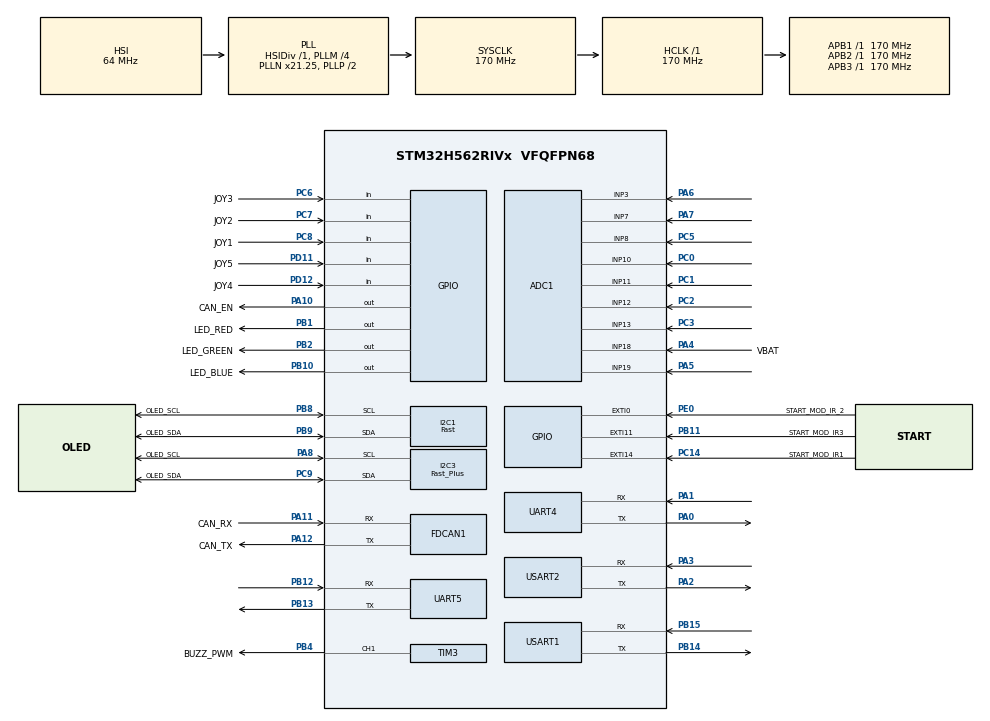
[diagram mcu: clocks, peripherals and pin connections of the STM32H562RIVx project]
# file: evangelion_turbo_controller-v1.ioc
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ADC1.Channel-0\#ChannelRegularConversion=ADC_CHANNEL_3
ADC1.Channel-1\#ChannelRegularConversion=ADC_CHANNEL_7
ADC1.Channel-2\#ChannelRegularConversion=ADC_CHANNEL_8
ADC1.Channel-3\#ChannelRegularConversion=ADC_CHANNEL_10
ADC1.Channel-4\#ChannelRegularConversion=ADC_CHANNEL_11
ADC1.Channel-5\#ChannelRegularConversion=ADC_CHANNEL_12
ADC1.Channel-6\#ChannelRegularConversion=ADC_CHANNEL_13
ADC1.Channel-7\#ChannelRegularConversion=ADC_CHANNEL_18
ADC1.Channel-8\#ChannelRegularConversion=ADC_CHANNEL_19
ADC1.ContinuousConvMode=ENABLE
ADC1.ConversionDataManagement=ADC_CONVERSIONDATA_DMA_CIRCULAR
ADC1.DMAContinuousRequests=ENABLE
ADC1.MonitoredBy-0\#ChannelRegularConversion=__NULL
ADC1.MonitoredBy-1\#ChannelRegularConversion=__NULL
ADC1.MonitoredBy-2\#ChannelRegularConversion=__NULL
ADC1.MonitoredBy-3\#ChannelRegularConversion=__NULL
ADC1.MonitoredBy-4\#ChannelRegularConversion=__NULL
ADC1.MonitoredBy-5\#ChannelRegularConversion=__NULL
ADC1.MonitoredBy-6\#ChannelRegularConversion=__NULL
ADC1.MonitoredBy-7\#ChannelRegularConversion=__NULL
ADC1.MonitoredBy-8\#ChannelRegularConversion=__NULL
ADC1.NbrOfConversion=9
ADC1.NbrOfConversionFlag=1
ADC1.OffsetNumber-0\#ChannelRegularConversion=ADC_OFFSET_NONE
ADC1.OffsetNumber-1\#ChannelRegularConversion=ADC_OFFSET_NONE
ADC1.OffsetNumber-2\#ChannelRegularConversion=ADC_OFFSET_NONE
ADC1.OffsetNumber-3\#ChannelRegularConversion=ADC_OFFSET_NONE
ADC1.OffsetNumber-4\#ChannelRegularConversion=ADC_OFFSET_NONE
ADC1.OffsetNumber-5\#ChannelRegularConversion=ADC_OFFSET_NONE
ADC1.OffsetNumber-6\#ChannelRegularConversion=ADC_OFFSET_NONE
ADC1.OffsetNumber-7\#ChannelRegularConversion=ADC_OFFSET_NONE
ADC1.OffsetNumber-8\#ChannelRegularConversion=ADC_OFFSET_NONE
ADC1.Overrun=ADC_OVR_DATA_OVERWRITTEN
ADC1.Rank-0\#ChannelRegularConversion=1
ADC1.Rank-1\#ChannelRegularConversion=2
ADC1.Rank-2\#ChannelRegularConversion=3
ADC1.Rank-3\#ChannelRegularConversion=4
ADC1.Rank-4\#ChannelRegularConversion=5
ADC1.Rank-5\#ChannelRegularConversion=6
ADC1.Rank-6\#ChannelRegularConversion=7
ADC1.Rank-7\#ChannelRegularConversion=8
ADC1.Rank-8\#ChannelRegularConversion=9
ADC1.SamplingTime-0\#ChannelRegularConversion=ADC_SAMPLETIME_6CYCLES_5
ADC1.SamplingTime-1\#ChannelRegularConversion=ADC_SAMPLETIME_6CYCLES_5
ADC1.SamplingTime-2\#ChannelRegularConversion=ADC_SAMPLETIME_6CYCLES_5
ADC1.SamplingTime-3\#ChannelRegularConversion=ADC_SAMPLETIME_6CYCLES_5
ADC1.SamplingTime-4\#ChannelRegularConversion=ADC_SAMPLETIME_6CYCLES_5
ADC1.SamplingTime-5\#ChannelRegularConversion=ADC_SAMPLETIME_6CYCLES_5
ADC1.SamplingTime-6\#ChannelRegularConversion=ADC_SAMPLETIME_6CYCLES_5
ADC1.SamplingTime-7\#ChannelRegularConversion=ADC_SAMPLETIME_6CYCLES_5
ADC1.SamplingTime-8\#ChannelRegularConversion=ADC_SAMPLETIME_24CYCLES_5
ADC1.master=1
BOOTPATH.BootPathName=LEGACY
BOOTPATH.UserSelectedBootPath=LEGACY
CORTEX_M33_NS.userName=CORTEX_M33
FDCAN1.AutoRetransmission=ENABLE
FDCAN1.CalculateBaudRateNominal=499999
FDCAN1.CalculateTimeBitNominal=2000
FDCAN1.CalculateTimeQuantumNominal=117.64705882352942
FDCAN1.DataPrescaler=20
FDCAN1.DataTimeSeg1=14
FDCAN1.DataTimeSeg2=2
FDCAN1.FrameFormat=FDCAN_FRAME_CLASSIC
FDCAN1.Mode=FDCAN_MODE_NORMAL
FDCAN1.NominalPrescaler=20
FDCAN1.NominalTimeSeg1=14
FDCAN1.NominalTimeSeg2=2
FDCAN1.StdFiltersNbr=1
GPDMA1.CIRCULARMODE_GPDMACH1=DISABLE
GPDMA1.CIRCULARMODE_GPDMACH2=DISABLE
GPDMA1.CIRCULARMODE_GPDMACH4=DISABLE
GPDMA1.CIRCULARMODE_GPDMACH5=DISABLE
GPDMA1.DATAHANDLING_GPDMACH2=NONE
GPDMA1.DESTBURSTLENGTH_GPDMACH2=1
GPDMA1.DESTDATAWIDTH_GPDMACH2=DMA_DEST_DATAWIDTH_BYTE
GPDMA1.DESTINC_GPDMACH1=DMA_DINC_INCREMENTED
GPDMA1.DESTINC_GPDMACH2=DMA_DINC_INCREMENTED
GPDMA1.DESTINC_GPDMACH4=DMA_DINC_INCREMENTED
GPDMA1.DESTINC_GPDMACH5=DMA_DINC_INCREMENTED
GPDMA1.IPHANDLE_GPDMACH1-SIMPLEREQUEST_GPDMACH1=__NULL
GPDMA1.IPHANDLE_GPDMACH2-SIMPLEREQUEST_GPDMACH2=__NULL
GPDMA1.IPHANDLE_GPDMACH4-SIMPLEREQUEST_GPDMACH4=__NULL
GPDMA1.IPHANDLE_GPDMACH5-SIMPLEREQUEST_GPDMACH5=__NULL
GPDMA1.LINKALLOCATEDPORT_CIRCULAR_GPDMACH4=DMA_LINK_ALLOCATED_PORT1
GPDMA1.LINKALLOCATEDPORT_CIRCULAR_GPDMACH5=DMA_LINK_ALLOCATED_PORT1
GPDMA1.PRIORITY_GPDMACH1=DMA_LOW_PRIORITY_HIGH_WEIGHT
GPDMA1.PRIORITY_GPDMACH2=DMA_LOW_PRIORITY_HIGH_WEIGHT
GPDMA1.PRIORITY_GPDMACH4=DMA_LOW_PRIORITY_HIGH_WEIGHT
GPDMA1.PRIORITY_GPDMACH5=DMA_LOW_PRIORITY_HIGH_WEIGHT
GPDMA1.REQUEST_GPDMACH1=GPDMA1_REQUEST_USART1_RX
GPDMA1.REQUEST_GPDMACH2=GPDMA1_REQUEST_USART2_RX
GPDMA1.REQUEST_GPDMACH4=GPDMA1_REQUEST_UART4_RX
GPDMA1.REQUEST_GPDMACH5=GPDMA1_REQUEST_UART5_RX
GPDMA1.SRCBURSTLENGTH_GPDMACH2=1
GPDMA1.SRCDATAWIDTH_GPDMACH1=DMA_SRC_DATAWIDTH_BYTE
GPDMA1.SRCDATAWIDTH_GPDMACH2=DMA_SRC_DATAWIDTH_BYTE
GPDMA1.SRCINC_GPDMACH2=DMA_SINC_FIXED
GPDMA2.CIRCULARMODE_GPDMACH0=ENABLE
GPDMA2.DESTDATAWIDTH_GPDMACH0=DMA_DEST_DATAWIDTH_HALFWORD
GPDMA2.DESTINC_GPDMACH0=DMA_DINC_INCREMENTED
GPDMA2.DESTINC_GPDMACH1=DMA_DINC_FIXED
GPDMA2.DIRECTION_GPDMACH1=DMA_MEMORY_TO_PERIPH
GPDMA2.IPHANDLE_GPDMACH0-SIMPLEREQUEST_GPDMACH0=__NULL
GPDMA2.IPHANDLE_GPDMACH1-SIMPLEREQUEST_GPDMACH1=__NULL
GPDMA2.LINKALLOCATEDPORT_CIRCULAR_GPDMACH0=DMA_LINK_ALLOCATED_PORT1
GPDMA2.PRIORITY_LL_CIRCULAR_GPDMACH0=DMA_LOW_PRIORITY_MID_WEIGHT
GPDMA2.REQUEST_GPDMACH0=GPDMA2_REQUEST_ADC1
GPDMA2.REQUEST_GPDMACH1=GPDMA2_REQUEST_I2C1_TX
GPDMA2.SRCDATAWIDTH_GPDMACH0=DMA_SRC_DATAWIDTH_HALFWORD
GPDMA2.SRCINC_GPDMACH1=DMA_SINC_INCREMENTED
I2C1.I2C_Speed_Mode=I2C_Fast
I2C1.Timing=0x10802D9B
I2C3.I2C_Speed_Mode=I2C_Fast_Plus
I2C3.Timing=0x00802172
Mcu.Family=STM32H5
Mcu.Name=STM32H562RIVx
Mcu.Package=VFQFPN68
NVIC.EXTI0_IRQn=true\:0\:0\:false\:false\:true\:true\:true\:true
NVIC.EXTI11_IRQn=true\:0\:0\:false\:false\:true\:true\:true\:true
NVIC.EXTI14_IRQn=true\:0\:0\:false\:false\:true\:true\:true\:true
NVIC.FDCAN1_IT0_IRQn=true\:0\:0\:false\:false\:true\:true\:true\:true
NVIC.FDCAN1_IT1_IRQn=true\:0\:0\:false\:false\:true\:true\:true\:true
NVIC.GPDMA1_Channel1_IRQn=true\:0\:0\:false\:false\:true\:false\:true\:true
NVIC.GPDMA1_Channel2_IRQn=true\:0\:0\:false\:false\:true\:false\:true\:true
NVIC.GPDMA1_Channel4_IRQn=true\:0\:0\:false\:false\:true\:false\:true\:true
NVIC.GPDMA1_Channel5_IRQn=true\:0\:0\:false\:false\:true\:false\:true\:true
NVIC.GPDMA2_Channel0_IRQn=true\:0\:0\:false\:false\:true\:false\:true\:true
NVIC.GPDMA2_Channel1_IRQn=true\:0\:0\:false\:false\:true\:false\:true\:true
NVIC.I2C1_EV_IRQn=true\:0\:0\:false\:false\:true\:true\:true\:true
NVIC.I2C3_ER_IRQn=true\:0\:0\:false\:false\:true\:true\:true\:true
NVIC.I2C3_EV_IRQn=true\:0\:0\:false\:false\:true\:true\:true\:true
NVIC.PriorityGroup=NVIC_PRIORITYGROUP_4
NVIC.TIM12_IRQn=true\:0\:0\:false\:false\:true\:true\:true\:true
NVIC.TIM13_IRQn=true\:0\:0\:false\:false\:true\:true\:true\:true
NVIC.TIM14_IRQn=true\:0\:0\:false\:false\:true\:true\:true\:true
NVIC.TIM15_IRQn=true\:0\:0\:false\:false\:true\:true\:true\:true
NVIC.TIM16_IRQn=true\:0\:0\:false\:false\:true\:true\:true\:true
NVIC.TIM17_IRQn=true\:0\:0\:false\:false\:true\:true\:true\:true
NVIC.TIM5_IRQn=true\:0\:0\:false\:false\:true\:true\:true\:true
NVIC.TIM6_IRQn=true\:0\:0\:false\:false\:true\:true\:true\:true
NVIC.TIM7_IRQn=true\:0\:0\:false\:false\:true\:true\:true\:true
NVIC.UART4_IRQn=true\:0\:0\:false\:false\:true\:true\:true\:true
NVIC.UART5_IRQn=true\:0\:0\:false\:false\:true\:true\:true\:true
NVIC.USART1_IRQn=true\:0\:0\:false\:false\:true\:true\:true\:true
NVIC.USART2_IRQn=true\:0\:0\:false\:false\:true\:true\:true\:true
PA0.Mode=Asynchronous
PA0.Signal=UART4_TX
PA1.Mode=Asynchronous
PA1.PinAttribute=Free
PA1.Signal=UART4_RX
PA10.GPIO_Label=CAN_EN
PA10.GPIO_PuPd=GPIO_PULLUP
PA10.PinAttribute=Free
PA10.Signal=GPIO_Output
PA11.GPIO_Label=CAN_RX
PA11.Mode=FDCAN_Activate
PA11.PinAttribute=Free
PA11.Signal=FDCAN1_RX
PA12.GPIO_Label=CAN_TX
PA12.Mode=FDCAN_Activate
PA12.PinAttribute=Free
PA12.Signal=FDCAN1_TX
PA13(JTMS/SWDIO).Mode=Serial_Wire
PA13(JTMS/SWDIO).Signal=DEBUG_JTMS-SWDIO
PA14(JTCK/SWCLK).Mode=Serial_Wire
PA14(JTCK/SWCLK).Signal=DEBUG_JTCK-SWCLK
PA2.Mode=Asynchronous
PA2.PinAttribute=Free
PA2.Signal=USART2_TX
PA3.Mode=Asynchronous
PA3.PinAttribute=Free
PA3.Signal=USART2_RX
PA4.GPIO_Label=VBAT
PA4.PinAttribute=Free
PA4.Signal=ADCx_INP18
PA5.PinAttribute=Free
PA5.Signal=ADCx_INP19
PA6.PinAttribute=Free
PA6.Signal=ADCx_INP3
PA7.PinAttribute=Free
PA7.Signal=ADCx_INP7
PA8.GPIO_Label=OLED_SCL
PA8.Mode=I2C
PA8.PinAttribute=Free
PA8.Signal=I2C3_SCL
PB1.GPIO_Label=LED_RED
PB1.PinAttribute=Free
PB1.Signal=GPIO_Output
PB10.GPIO_Label=LED_BLUE
PB10.PinAttribute=Free
PB10.Signal=GPIO_Output
PB11.GPIO_Label=START_MOD_IR3
PB11.GPIO_ModeDefaultEXTI=GPIO_MODE_IT_RISING_FALLING
PB11.GPIO_PuPd=GPIO_NOPULL
PB11.PinAttribute=Free
PB11.Signal=GPXTI11
PB12.Mode=Asynchronous
PB12.PinAttribute=Free
PB12.Signal=UART5_RX
PB13.Mode=Asynchronous
PB13.PinAttribute=Free
PB13.Signal=UART5_TX
PB14.Mode=Asynchronous
PB14.PinAttribute=Free
PB14.Signal=USART1_TX
PB15.Mode=Asynchronous
PB15.PinAttribute=Free
PB15.Signal=USART1_RX
PB2.GPIO_Label=LED_GREEN
PB2.PinAttribute=Free
PB2.Signal=GPIO_Output
PB4(NJTRST).GPIO_Label=BUZZ_PWM
PB4(NJTRST).PinAttribute=Free
PB4(NJTRST).Signal=S_TIM3_CH1
PB8.GPIO_Label=OLED_SCL
PB8.Mode=I2C
PB8.Signal=I2C1_SCL
PB9.GPIO_Label=OLED_SDA
PB9.Mode=I2C
PB9.Signal=I2C1_SDA
PC0.PinAttribute=Free
PC0.Signal=ADCx_INP10
PC1.Signal=ADCx_INP11
PC14-OSC32_IN(OSC32_IN).GPIO_Label=START_MOD_IR1
PC14-OSC32_IN(OSC32_IN).GPIO_ModeDefaultEXTI=GPIO_MODE_IT_RISING_FALLING
PC14-OSC32_IN(OSC32_IN).GPIO_PuPd=GPIO_NOPULL
PC14-OSC32_IN(OSC32_IN).Signal=GPXTI14
PC2.Signal=ADCx_INP12
PC3.Signal=ADCx_INP13
PC5.PinAttribute=Free
PC5.Signal=ADCx_INP8
PC6.GPIO_Label=JOY3
PC6.GPIO_PuPd=GPIO_PULLUP
PC6.PinAttribute=Free
PC6.Signal=GPIO_Input
PC7.GPIO_Label=JOY2
PC7.GPIO_PuPd=GPIO_PULLUP
PC7.PinAttribute=Free
PC7.Signal=GPIO_Input
PC8.GPIO_Label=JOY1
PC8.GPIO_PuPd=GPIO_PULLUP
PC8.PinAttribute=Free
PC8.Signal=GPIO_Input
PC9.GPIO_Label=OLED_SDA
PC9.Mode=I2C
PC9.PinAttribute=Free
PC9.Signal=I2C3_SDA
PD11.GPIO_Label=JOY5
PD11.GPIO_PuPd=GPIO_PULLUP
PD11.PinAttribute=Free
PD11.Signal=GPIO_Input
PD12.GPIO_Label=JOY4
PD12.GPIO_PuPd=GPIO_PULLUP
PD12.PinAttribute=Free
PD12.Signal=GPIO_Input
PE0.GPIO_Label=START_MOD_IR_2
PE0.GPIO_ModeDefaultEXTI=GPIO_MODE_IT_RISING_FALLING
PE0.GPIO_PuPd=GPIO_NOPULL
PE0.PinAttribute=Free
PE0.Signal=GPXTI0
ProjectManager.HeapSize=0x200
ProjectManager.StackSize=0x400
ProjectManager.TargetToolchain=STM32CubeIDE
RCC.ADCFreq_Value=170000000
RCC.AHBFreq_Value=170000000
RCC.APB1Freq_Value=170000000
RCC.APB1TimFreq_Value=170000000
RCC.APB2Freq_Value=170000000
RCC.APB2TimFreq_Value=170000000
RCC.APB3Freq_Value=170000000
RCC.CSI_VALUE=4000000
RCC.CortexFreq_Value=170000000
RCC.EPOD_VALUE=64000000
RCC.FDCANClockSelection=RCC_FDCANCLKSOURCE_PLL1Q
RCC.HCLKFreq_Value=170000000
RCC.HSE_Timout=200
RCC.HSE_VALUE=48000000
RCC.HSI48_VALUE=48000000
RCC.HSIDiv=RCC_HSI_DIV1
RCC.HSI_VALUE=64000000
RCC.LSE_VALUE=32768
RCC.LSIRC_VALUE=32000
RCC.PLL2FRACN=0
RCC.PLL2Source=RCC_PLL2_SOURCE_HSI
RCC.PLL3FRACN=0
RCC.PLL3Source=RCC_PLL3_SOURCE_HSI
RCC.PLL3_VCI_Range-AdvancedSettings=RCC_PLL3_VCIRANGE_0
RCC.PLLFRACN=2048
RCC.PLLM=4
RCC.PLLN=21
RCC.PLLSourceVirtual=RCC_PLL1_SOURCE_HSI
RCC.SYSCLKFreq_VALUE=170000000
RCC.SYSCLKSource=RCC_SYSCLKSOURCE_PLLCLK
RCC.USBFreq_Value=48000000
RCC.VCOOutputFreq_Value=340000000
SH.ADCx_INP10.0=ADC1_INP10,IN10-Single-Ended
SH.ADCx_INP11.0=ADC1_INP11,IN11-Single-Ended
SH.ADCx_INP12.0=ADC1_INP12,IN12-Single-Ended
SH.ADCx_INP13.0=ADC1_INP13,IN13-Single-Ended
SH.ADCx_INP18.0=ADC1_INP18,IN18-Single-Ended
SH.ADCx_INP19.0=ADC1_INP19,IN19-Single-Ended
SH.ADCx_INP3.0=ADC1_INP3,IN3-Single-Ended
SH.ADCx_INP7.0=ADC1_INP7,IN7-Single-Ended
SH.ADCx_INP8.0=ADC1_INP8,IN8-Single-Ended
SH.S_TIM3_CH1.0=TIM3_CH1,PWM Generation1 CH1
TIM12.PeriodNoDither=5000-1
TIM12.Prescaler=1700-1
TIM13.PeriodNoDither=1000-1
TIM13.Prescaler=170-1
TIM14.PeriodNoDither=1000-1
TIM14.Prescaler=6800-1
TIM15.PeriodNoDither=65535
TIM15.Prescaler=170-1
TIM16.PeriodNoDither=1000-1
TIM16.Prescaler=170-1
TIM17.PeriodNoDither=1000-1
TIM17.Prescaler=1700-1
TIM3.Channel-PWM\ Generation1\ CH1=TIM_CHANNEL_1
TIM4.Prescaler=17000-1
TIM5.PeriodNoDither=65535
TIM5.Prescaler=17000-1
TIM6.Prescaler=17000-1
TIM7.Prescaler=17000-1
UART4.DataInvertParam=UART_ADVFEATURE_DATAINV_DISABLE
UART4.SwapParam=UART_ADVFEATURE_SWAP_DISABLE
USART1.VirtualMode-Asynchronous=VM_ASYNC
USART2.VirtualMode-Asynchronous=VM_ASYNC
VP_BOOTPATH_VS_BOOTPATH.Mode=BP_Activate
VP_CORTEX_M33_NS_VS_Hclk.Mode=Hclk_Mode
VP_GPDMA1_VS_GPDMACH1.Mode=SIMPLEREQUEST_GPDMACH1
VP_GPDMA1_VS_GPDMACH2.Mode=SIMPLEREQUEST_GPDMACH2
VP_GPDMA1_VS_GPDMACH4.Mode=SIMPLEREQUEST_GPDMACH4
VP_GPDMA1_VS_GPDMACH5.Mode=SIMPLEREQUEST_GPDMACH5
VP_GPDMA2_VS_GPDMACH0.Mode=SIMPLEREQUEST_GPDMACH0
VP_GPDMA2_VS_GPDMACH1.Mode=SIMPLEREQUEST_GPDMACH1
VP_MEMORYMAP_VS_MEMORYMAP.Mode=CurAppReg
VP_PWR_VS_LPOM.Mode=PowerOptimisation
VP_PWR_VS_SECSignals.Mode=Security/Privilege
VP_TIM12_VS_ClockSourceINT.Mode=Internal
VP_TIM13_VS_ClockSourceINT.Mode=Enable_Timer
VP_TIM14_VS_ClockSourceINT.Mode=Enable_Timer
VP_TIM15_VS_ClockSourceINT.Mode=Internal
VP_TIM16_VS_ClockSourceINT.Mode=Enable_Timer
VP_TIM17_VS_ClockSourceINT.Mode=Enable_Timer
VP_TIM4_VS_OPM.Mode=OPM_bit
VP_TIM5_VS_OPM.Mode=OPM_bit
VP_TIM6_VS_ClockSourceINT.Mode=Enable_Timer
VP_TIM7_VS_ClockSourceINT.Mode=Enable_Timer
board=custom

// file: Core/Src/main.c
/* USER CODE BEGIN Header */
/**
  ******************************************************************************
  * @file           : main.c
  * @brief          : Main program body
  ******************************************************************************
  * @attention
  *
  * Copyright (c) 2026 STMicroelectronics.
  * All rights reserved.
  *
  * This software is licensed under terms that can be found in the LICENSE file
  * in the root directory of this software component.
  * If no LICENSE file comes with this software, it is provided AS-IS.
  *
  ******************************************************************************
  */
/* USER CODE END Header */
#include "main.h"

/* USER CODE BEGIN Includes */
#include "stdlib.h"
#include "MY_INCLUDES.h"

#include "fonts.h"
#include "ssd1306.h"
/* USER CODE END Includes */

/* USER CODE BEGIN PD */
#define DMA_HANDLE_UART1 &handle_GPDMA1_Channel1
#define DMA_HANDLE_UART2 &handle_GPDMA1_Channel2
#define DMA_HANDLE_UART4 &handle_GPDMA1_Channel4
#define DMA_HANDLE_UART5 &handle_GPDMA1_Channel5

#define CAN_ID_CTRL  60
#define CAN_ID_DRV0  67
#define CAN_ID_DRV1  69

//==================================================== WORKING SETUP
#define MAIN_FREQ 1000
#define SIDE_FREQ 100
#define OLED_FREQ 25
#define true 1
#define TRUE 1
#define false 0
#define FALSE 0
#define LEFT 0
#define RIGHT 1

//============etc
#define ABS(x) ((x) < 0 ? -(x) : (x))

//option IDs
#define OPTION_ID_BATTERY 1
#define OPTION_ID_START_MOD 2
#define OPTION_ID_LUNA_DIST 3
#define OPTION_ID_LUNA_AMP 4
#define OPTION_ID_LINES 6
#define OPTION_ID_ACCEL 7
#define OPTION_ID_GYRO 8
#define OPTION_ID_IMU_PEAK 9
#define OPTION_ID_SET_MOTS 10
#define OPTION_ID_DEBUG 11
#define OPTION_ID_ATTACK_MODE 12

//==================================================== BATTERY
#define BATTERY_VOLTAGE_COMPENSATION 	1
#define MIN_BATTERY_VOLTAGE_PER_CELL 	3.45
#define Reference_Voltage				3.311		// V
#define Voltage_Resistor_Top 			91.0		// kOhm
#define Voltage_Resistor_Bottom  		10.0		// kOhm
#define ADC_MAX_VALUE					4096

//==================================================== OLED
#define _ssd1306_SetCursor(x, y) ssd1306_SetCursor(y, x)
#define BIG 1
#define SMALL 0

#define _ARR_UP '('
#define _ARR_DOWN '@'
#define _CHECKBOX_EMPTY '^'
#define _CHECKBOX_CHECKED '$'
#define _CHECKBOX_EMPTY_BIG ')'
#define _CHECKBOX_CHECKED_BIG '\''
#define _CANCEL '}'
#define _APPLY '{'

//=============================================================================================================
//=============================================================================================================			START MOD CODE
//=============================================================================================================
#define RISING 		1
#define FALLING		2
#define TIMEOUT		3

#define RC5				1
#define SIRC			2
#define UNKNOWN			0
#define SAVED_STATUS 	5

#define RC5_Short   889      // 889 us
#define RC5_Long    1778     // 1778 us
#define SIRC_Short  600+50      // 600 us
#define SIRC_Long   1200+50     // 1200 us
#define Margin      300

// Module Status
#define STARTUP		1
#define	PPROGRAMMED	2
#define	READY		3
#define	RC5_START	4
#define SIRC_START	5
#define	STOP		6

// Led Commands
#define ON			2
#define OFF			3
#define BLINK_SLOW	4
#define BLINK_FAST	5
#define TICK		6

/* USER CODE END PD */

/* USER CODE BEGIN PM */
typedef struct {
	uint8_t DONT_USE_MOTORS;
	uint8_t ALWAYS_IN_BATTLE;
	uint8_t IGNORE_START_MODULE;
	uint8_t LINE_SENSORS_ALWAYS_IN;
	uint8_t IGNORE_ACCEL;
	uint8_t DONT_INITIALIZE_LIDARS;
} Settings_t;

typedef enum {
	IN,
	OUT
} LineState_t;

typedef enum {
	STRAIGHT,
	CURVE,
	FOLLOW_LINER,
	FOLLOW_ATTACKER,
	COUNT,
} RobotAttackMode_t;

typedef enum
{
	IDLE,
	BEFORE_ATTACK_WAIT,
	BEFORE_ATTACK_TASK,
	AFTER_TASK_RAM_QUCKIE,
	AFTER_TASK_RAM_CHILL,
	ATTACK,
} RobotState_t;

typedef enum {
	_NOTHING,
	_UP,
	_DOWN,
	_LEFT,
	_RIGHT,
	_CENTER,
	_BUTTON_REBOUNCE,
} JoystickMode_t;

typedef struct {
	LineState_t Line;
	uint16_t RawLineA;
	uint16_t RawLineB;
    uint16_t Distance;
    uint16_t LidarAmp;
    uint16_t LidarTemp;
} SensorData_t;

typedef struct {
	uint8_t Switch1;
	uint8_t Switch2;
	uint8_t Switch3;
	JoystickMode_t Joystick;
	uint8_t MenuOption;
} Interface_t;

typedef struct
{
	int16_t x;
	int16_t y;
	int16_t z;
	int16_t peak;
} Vector_t;

typedef struct {
	uint8_t inBattle;
	RobotAttackMode_t AttackMode;
	uint16_t Voltage;
	uint16_t CellVoltage;
	RobotState_t State;
	Interface_t Interface;
	uint8_t DriverTemp;
	uint16_t StartDelayTimer;
} RobotData_t;

typedef struct {
	uint8_t CurrentAddres;
	uint8_t Started;
	uint8_t StartedViaInterface;
	uint8_t StartedViaSwitch;
	uint16_t Delay;
	uint16_t VolatileDelayTimer;
} StartModData_t;

typedef struct
{
	int8_t L;
	int8_t R;
} Speed_t;

typedef struct
{
	uint8_t L;
	uint8_t R;
} Speed_directional_t;

typedef struct
{
	Speed_t Requested;
	Speed_t Set;
	Speed_directional_t CAN;
} MotorSpeed_t;

typedef struct {
    const char *name;
    uint8_t id;
} MenuOption_t;

/* USER CODE END PM */

ADC_HandleTypeDef hadc1;
DMA_NodeTypeDef Node_GPDMA2_Channel0;
DMA_QListTypeDef List_GPDMA2_Channel0;
DMA_HandleTypeDef handle_GPDMA2_Channel0;

FDCAN_HandleTypeDef hfdcan1;

I2C_HandleTypeDef hi2c1;
I2C_HandleTypeDef hi2c3;
DMA_HandleTypeDef handle_GPDMA2_Channel1;

TIM_HandleTypeDef htim3;
TIM_HandleTypeDef htim4;
TIM_HandleTypeDef htim5;
TIM_HandleTypeDef htim6;
TIM_HandleTypeDef htim7;
TIM_HandleTypeDef htim12;
TIM_HandleTypeDef htim13;
TIM_HandleTypeDef htim14;
TIM_HandleTypeDef htim15;
TIM_HandleTypeDef htim16;
TIM_HandleTypeDef htim17;

UART_HandleTypeDef huart4;
UART_HandleTypeDef huart5;
UART_HandleTypeDef huart1;
UART_HandleTypeDef huart2;
DMA_HandleTypeDef handle_GPDMA1_Channel4;
DMA_HandleTypeDef handle_GPDMA1_Channel5;
DMA_HandleTypeDef handle_GPDMA1_Channel1;
DMA_HandleTypeDef handle_GPDMA1_Channel2;

/* USER CODE BEGIN PV */
//CAN
FDCAN_RxHeaderTypeDef 		CAN_RX_Header; 		//CAN Bus Transmit Header
FDCAN_TxHeaderTypeDef 		CAN_TX_Header; 		//CAN Bus Receive Header
uint8_t                     CAN_TX[8];
uint8_t                     CAN_RX[8];
FDCAN_FilterTypeDef 		CAN_Filter;

volatile int32_t dupa=0;
volatile int32_t dupa2=0;
uint16_t actual_init_freq=FREQ_STARTING;
int16_t ERROR_FLAG=0;

//sensors
uint8_t  UART1_RX[9];
uint8_t  UART2_RX[9];
uint8_t  UART4_RX[9];
uint8_t  UART5_RX[9];
uint8_t  UART_TX[9];

SensorData_t FrontLeft={0};
SensorData_t FrontRight={0};
SensorData_t BackLeft={0};
SensorData_t BackRight={0};
RobotData_t Eva={0};
MotorSpeed_t Motors={0};
StartModData_t StartMod={0};
Settings_t Settings={0};

uint8_t lastSeen = LEFT;
uint8_t before_attack_rotation_direction = LEFT;

volatile uint16_t ADC_BUFFER[9];
float BATTERY_CONSTANT;

//performance!
static uint32_t last_total = 0;
static uint32_t last_idle = 0;
volatile uint32_t cpu_idle_cycles = 0;
volatile uint32_t cpu_load_permille = 0;
volatile uint8_t MCU_LOAD = 0;
volatile uint8_t MCU_LOAD_MAX = 0;

//============================		START MOD CODE
uint8_t Module_State = STARTUP;
static uint8_t Dohyo_ID=0;
uint8_t MAX_ACCELERATION=0;
/* USER CODE END PV */

void SystemClock_Config(void);
static void MX_GPIO_Init(void);
static void MX_GPDMA1_Init(void);
static void MX_GPDMA2_Init(void);
static void MX_ADC1_Init(void);
static void MX_FDCAN1_Init(void);
static void MX_I2C3_Init(void);
static void MX_TIM3_Init(void);
static void MX_UART4_Init(void);
static void MX_UART5_Init(void);
static void MX_USART2_UART_Init(void);
static void MX_USART1_UART_Init(void);
static void MX_TIM16_Init(void);
static void MX_TIM17_Init(void);
static void MX_I2C1_Init(void);
static void MX_TIM14_Init(void);
static void MX_TIM12_Init(void);
static void MX_TIM13_Init(void);
static void MX_TIM15_Init(void);
static void MX_TIM6_Init(void);
static void MX_TIM7_Init(void);
static void MX_TIM4_Init(void);
static void MX_TIM5_Init(void);
/* USER CODE BEGIN PFP */
static void LIDARS_INIT(UART_HandleTypeDef *huart, DMA_HandleTypeDef *hdma, uint8_t *RX);
static void PLAY_FREQ(uint16_t f_hz);
static void COOKED(uint8_t error_code);
static void SORT(uint16_t *array, uint8_t length);
static void GET_LINE_SENSORS(void);
static void GET_START_MOD(void);
static void STRAIGHT_ATTACK(void);
static void CURVE_ATTACK(void);
static void FOLLOWLINER_ATTACK(void);
static void FOLLOW_ATTACKER_ATTACK(void);
static void WATCHDOG(void);
static void GET_LAST_SEEN_ROTATIONE(void);
static void TASK_BEFORE_ATTACK(void);
static void SET_MOTORS(int8_t l, int8_t r);
static void SET_RAW_MOTORS(int8_t l, int8_t r);
static void _ssd1306_WriteInTheMiddle(char *text, uint8_t y, uint8_t font);
static void _ssd1306_WriteString(char* str, uint8_t font);
static void MOTOR_DRIVER_INIT(uint8_t DRV_SELF_ADDRESS);
static uint8_t ARE_ELEMENTS_EQUAL(const uint8_t *a, const uint8_t *b, uint8_t n);
static int8_t Acceleration_Compensation_R(int8_t Duty);
static int8_t Acceleration_Compensation_L(int8_t Duty);
static void OLED(void);
static inline void DWT_Init(void);

//============================		START MOD CODE
static void Interrupt10Hz(void);
static void Interrupt(uint8_t Edge);
static void Received_RC5_Frame(uint8_t Addres, uint8_t Command);
static void Received_SIRC_Frame(uint8_t Addres, uint8_t Command);
static uint8_t LED_GREEN_Control(uint8_t Command, uint8_t Data);
static uint8_t LED_RED_Control(uint8_t Command, uint8_t Data);
static uint8_t LED_BLUE_Control(uint8_t Command, uint8_t Data);
/* USER CODE END PFP */

int main(void)
{

  /* USER CODE BEGIN 1 */
    Eva.AttackMode = DEFAULT_ATTACK_MODE_ID;
    MAX_ACCELERATION = MAX_MOTOR_ACCELERATION_NOT_DECELERATION_BY_CONTROLLER;

  /* USER CODE END 1 */

  /* MCU Configuration--------------------------------------------------------*/

  /* Reset of all peripherals, Initializes the Flash interface and the Systick. */
  HAL_Init();

  /* USER CODE BEGIN Init */
  HAL_Delay(100);
  /* USER CODE END Init */

  /* Configure the system clock */
  SystemClock_Config();

  /* Initialize all configured peripherals */
  MX_GPIO_Init();
  MX_GPDMA1_Init();
  MX_GPDMA2_Init();
  MX_ADC1_Init();
  MX_FDCAN1_Init();
  MX_I2C3_Init();
  MX_TIM3_Init();
  MX_UART4_Init();
  MX_UART5_Init();
  MX_USART2_UART_Init();
  MX_USART1_UART_Init();
  MX_TIM16_Init();
  MX_TIM17_Init();
  MX_I2C1_Init();
  MX_TIM14_Init();
  MX_TIM12_Init();
  MX_TIM13_Init();
  MX_TIM15_Init();
  MX_TIM6_Init();
  MX_TIM7_Init();
  MX_TIM4_Init();
  MX_TIM5_Init();
  /* USER CODE BEGIN 2 */

  static uint8_t init_text_height = 0;
  static uint8_t init_secondary_text_height = 20;
  static uint8_t init_everywhere_delay = 50;

	//INTIT
	actual_init_freq = actual_init_freq + FREQ_STEP_INIT;
	PLAY_FREQ(actual_init_freq);
	if(ssd1306_Init()==0)
		Error_Handler();
	ssd1306_Clear();
	ssd1306_SetColor(White);
	ssd1306_Fill();
	ssd1306_UpdateScreen();
	HAL_Delay(init_everywhere_delay);

	//CAN FILTERS
	ssd1306_Clear();
	_ssd1306_WriteInTheMiddle("CAN", init_text_height, BIG);
	_ssd1306_WriteInTheMiddle("initialize", init_secondary_text_height, SMALL);
	ssd1306_UpdateScreen();
	HAL_Delay(init_everywhere_delay);
	CAN_Filter.IdType = FDCAN_STANDARD_ID;
	CAN_Filter.FilterIndex = 0;
	CAN_Filter.FilterType = FDCAN_FILTER_DISABLE;
	CAN_Filter.FilterConfig = FDCAN_FILTER_TO_RXFIFO0;
	CAN_Filter.FilterID1 = 0;
	CAN_Filter.FilterID2 = 0;
	HAL_FDCAN_ConfigFilter(&hfdcan1, &CAN_Filter);

	//CAN SETTINGS
	CAN_TX_Header.Identifier = CAN_ID_CTRL;
	CAN_TX_Header.IdType = FDCAN_STANDARD_ID;
	CAN_TX_Header.TxFrameType = FDCAN_DATA_FRAME;
	CAN_TX_Header.DataLength = FDCAN_DLC_BYTES_8;
	CAN_TX_Header.ErrorStateIndicator = FDCAN_ESI_ACTIVE;
	CAN_TX_Header.TxEventFifoControl = FDCAN_NO_TX_EVENTS;
	CAN_TX_Header.MessageMarker = 0;
	CAN_TX_Header.FDFormat = FDCAN_CLASSIC_CAN;
	CAN_TX_Header.BitRateSwitch = FDCAN_BRS_OFF;

	BATTERY_CONSTANT = ((Voltage_Resistor_Top + Voltage_Resistor_Bottom) / Voltage_Resistor_Bottom) * Reference_Voltage / 4096 * 100;

	Settings.ALWAYS_IN_BATTLE = DEFAULT_SETTING_ALWAYS_IN_BATTLE;
	Settings.DONT_INITIALIZE_LIDARS = DEFAULT_SETTING_DONT_INITIALIZE_LIDARS;
	Settings.DONT_USE_MOTORS = DEFAULT_SETTING_DONT_USE_MOTORS;
	Settings.IGNORE_START_MODULE = DEFAULT_SETTING_IGNORE_START_MODULE;

	lastSeen = LEFT;
	Eva.inBattle = FALSE;
	Eva.State = IDLE;
	Eva.AttackMode = DEFAULT_ATTACK_MODE_ID;
	Eva.StartDelayTimer = 0;

	//GPIO LED MISC
	actual_init_freq = actual_init_freq + FREQ_STEP_INIT;
	PLAY_FREQ(actual_init_freq);
	HAL_GPIO_WritePin(LED_RED_GPIO_Port, LED_RED_Pin, 0);
	HAL_GPIO_WritePin(LED_BLUE_GPIO_Port, LED_BLUE_Pin, 0);
	HAL_GPIO_WritePin(LED_GREEN_GPIO_Port, LED_GREEN_Pin, 1);
	HAL_GPIO_WritePin(CAN_EN_GPIO_Port, CAN_EN_Pin, 1);
	HAL_Delay(init_everywhere_delay);

	//start mode setup
	//============================		START MOD CODE
    Module_State = STARTUP;
	ssd1306_Clear();
	_ssd1306_WriteInTheMiddle("START", init_text_height, BIG);
	_ssd1306_WriteInTheMiddle("MODULE", init_secondary_text_height, SMALL);
	ssd1306_UpdateScreen();
	HAL_Delay(init_everywhere_delay);
	//  Signal Power UP
	HAL_GPIO_WritePin(LED_RED_GPIO_Port, LED_RED_Pin, GPIO_PIN_SET);
	HAL_Delay(125);
	HAL_GPIO_WritePin(LED_RED_GPIO_Port, LED_RED_Pin, GPIO_PIN_RESET);
	HAL_GPIO_WritePin(LED_BLUE_GPIO_Port, LED_BLUE_Pin, GPIO_PIN_SET);
	HAL_Delay(125);
	HAL_GPIO_WritePin(LED_BLUE_GPIO_Port, LED_BLUE_Pin, GPIO_PIN_RESET);
	HAL_GPIO_WritePin(LED_GREEN_GPIO_Port, LED_GREEN_Pin, GPIO_PIN_SET);
	HAL_Delay(250);
	HAL_GPIO_WritePin(LED_GREEN_GPIO_Port, LED_GREEN_Pin, GPIO_PIN_RESET);

	//LUNAS
	ssd1306_Clear();
	_ssd1306_WriteInTheMiddle("LIDARS", init_text_height, BIG);
	ssd1306_UpdateScreen();
	HAL_Delay(init_everywhere_delay);
	actual_init_freq = actual_init_freq + FREQ_STEP_INIT;
	PLAY_FREQ(actual_init_freq);
	if(Settings.DONT_INITIALIZE_LIDARS == FALSE)
	{
		ssd1306_Clear();
		_ssd1306_WriteInTheMiddle("LIDARS", init_text_height, BIG);
		_ssd1306_WriteInTheMiddle("front right", init_secondary_text_height, SMALL);
		ssd1306_UpdateScreen();
		LIDARS_INIT(&huart2, DMA_HANDLE_UART2, UART2_RX);

		ssd1306_Clear();
		_ssd1306_WriteInTheMiddle("LIDARS", init_text_height, BIG);
		_ssd1306_WriteInTheMiddle("front left", init_secondary_text_height, SMALL);
		ssd1306_UpdateScreen();
		LIDARS_INIT(&huart5, DMA_HANDLE_UART5, UART5_RX);

		ssd1306_Clear();
		_ssd1306_WriteInTheMiddle("LIDARS", init_text_height, BIG);
		_ssd1306_WriteInTheMiddle("back left", init_secondary_text_height, SMALL);
		ssd1306_UpdateScreen();
		LIDARS_INIT(&huart1, DMA_HANDLE_UART1, UART1_RX);

		ssd1306_Clear();
		_ssd1306_WriteInTheMiddle("LIDAR", init_text_height, BIG);
		_ssd1306_WriteInTheMiddle("back right", init_secondary_text_height, SMALL);
		ssd1306_UpdateScreen();
		LIDARS_INIT(&huart4, DMA_HANDLE_UART4, UART4_RX);
		/*
		uart1 = back left
		uart2 = front right
		uart4 = back right
		uart5 = front left
		*/
	}

	//ADC
	ssd1306_Clear();
	_ssd1306_WriteInTheMiddle("ADCs", init_text_height, BIG);
	ssd1306_UpdateScreen();
	HAL_Delay(init_everywhere_delay);
	actual_init_freq = actual_init_freq + FREQ_STEP_INIT;
	PLAY_FREQ(actual_init_freq);
	if (HAL_ADCEx_Calibration_Start(&hadc1, ADC_SINGLE_ENDED) != HAL_OK)
	  COOKED(ADC_INIT_ERR);
	HAL_Delay(50);

	if (HAL_ADC_Start_DMA(&hadc1, (uint32_t*)ADC_BUFFER, 9) != HAL_OK)
	  COOKED(ADC_INIT_ERR);

	//CAN
	ssd1306_Clear();
	_ssd1306_WriteInTheMiddle("DRVs", init_text_height, BIG);
	_ssd1306_WriteInTheMiddle("CAN start", init_secondary_text_height, SMALL);
	ssd1306_UpdateScreen();
	HAL_Delay(init_everywhere_delay);
	actual_init_freq = actual_init_freq + FREQ_STEP_INIT;
	PLAY_FREQ(actual_init_freq);
	if (HAL_FDCAN_Start(&hfdcan1) != HAL_OK)
		Error_Handler();
	HAL_FDCAN_ActivateNotification(&hfdcan1, FDCAN_IT_RX_FIFO0_NEW_MESSAGE, 0);
	HAL_FDCAN_AddMessageToTxFifoQ(&hfdcan1, &CAN_TX_Header, CAN_TX);

	//DRV1
	ssd1306_Clear();
	_ssd1306_WriteInTheMiddle("DRVs", init_text_height, BIG);
	_ssd1306_WriteInTheMiddle("DRV 0 init", init_secondary_text_height, SMALL);
	ssd1306_UpdateScreen();
	HAL_Delay(init_everywhere_delay);
	MOTOR_DRIVER_INIT(CAN_ID_DRV0);

	//DRV2
	ssd1306_Clear();
	_ssd1306_WriteInTheMiddle("DRVs", init_text_height, BIG);
	_ssd1306_WriteInTheMiddle("DRV 1 init", init_secondary_text_height, SMALL);
	ssd1306_UpdateScreen();
	HAL_Delay(init_everywhere_delay);
	MOTOR_DRIVER_INIT(CAN_ID_DRV1);

	//Performance
	ssd1306_Clear();
	_ssd1306_WriteInTheMiddle("MCU", init_text_height, BIG);
	_ssd1306_WriteInTheMiddle("performance", init_secondary_text_height, SMALL);
	ssd1306_UpdateScreen();
	HAL_Delay(init_everywhere_delay);
	actual_init_freq = actual_init_freq + FREQ_STEP_INIT;
	PLAY_FREQ(actual_init_freq);
	DWT_Init();

	//Interrupts
	ssd1306_Clear();
	_ssd1306_WriteInTheMiddle("ITs", init_text_height, BIG);
	_ssd1306_WriteInTheMiddle("start", init_secondary_text_height, SMALL);
	ssd1306_UpdateScreen();
	HAL_Delay(init_everywhere_delay);
	actual_init_freq = actual_init_freq + FREQ_STEP_INIT;
	PLAY_FREQ(actual_init_freq);
	HAL_TIM_Base_Start_IT(&htim12); //10Hz start mod
	HAL_TIM_Base_Start_IT(&htim13); //1Khz start mod
	HAL_TIM_Base_Start_IT(&htim14); //25Hz oled
	HAL_TIM_Base_Start_IT(&htim16); //1000Hz
	HAL_TIM_Base_Start_IT(&htim17); //100Hz
	HAL_TIM_Base_Start_IT(&htim15); // START_MOD
	HAL_TIM_Base_Start(&htim6);
	HAL_TIM_Base_Start(&htim7);

	HAL_GPIO_WritePin(LED_RED_GPIO_Port, LED_RED_Pin, 0);
	HAL_GPIO_WritePin(LED_BLUE_GPIO_Port, LED_BLUE_Pin, 0);
	HAL_GPIO_WritePin(LED_GREEN_GPIO_Port, LED_GREEN_Pin, 0);
	PLAY_FREQ(0);
	ssd1306_Clear();
	_ssd1306_WriteInTheMiddle("TURBO", 2, SMALL);
	_ssd1306_WriteInTheMiddle("EVA++", 10, BIG);
	ssd1306_UpdateScreen();

  /* USER CODE END 2 */

  /* Infinite loop */
  /* USER CODE BEGIN WHILE */
  while (1)
  {
	uint32_t start = DWT->CYCCNT;
	__WFI();
	cpu_idle_cycles += (DWT->CYCCNT - start);
	CAN_TX_Header.DataLength = FDCAN_DLC_BYTES_4;
    /* USER CODE END WHILE */

  }
}

void SystemClock_Config(void)
{
  RCC_OscInitTypeDef RCC_OscInitStruct = {0};
  RCC_ClkInitTypeDef RCC_ClkInitStruct = {0};

  /** Configure the main internal regulator output voltage
  */
  __HAL_PWR_VOLTAGESCALING_CONFIG(PWR_REGULATOR_VOLTAGE_SCALE1);

  while(!__HAL_PWR_GET_FLAG(PWR_FLAG_VOSRDY)) {}

  /** Initializes the RCC Oscillators according to the specified parameters
  * in the RCC_OscInitTypeDef structure.
  */
  RCC_OscInitStruct.OscillatorType = RCC_OSCILLATORTYPE_HSI;
  RCC_OscInitStruct.HSIState = RCC_HSI_ON;
  RCC_OscInitStruct.HSIDiv = RCC_HSI_DIV1;
  RCC_OscInitStruct.HSICalibrationValue = RCC_HSICALIBRATION_DEFAULT;
  RCC_OscInitStruct.PLL.PLLState = RCC_PLL_ON;
  RCC_OscInitStruct.PLL.PLLSource = RCC_PLL1_SOURCE_HSI;
  RCC_OscInitStruct.PLL.PLLM = 4;
  RCC_OscInitStruct.PLL.PLLN = 21;
  RCC_OscInitStruct.PLL.PLLP = 2;
  RCC_OscInitStruct.PLL.PLLQ = 2;
  RCC_OscInitStruct.PLL.PLLR = 2;
  RCC_OscInitStruct.PLL.PLLRGE = RCC_PLL1_VCIRANGE_3;
  RCC_OscInitStruct.PLL.PLLVCOSEL = RCC_PLL1_VCORANGE_WIDE;
  RCC_OscInitStruct.PLL.PLLFRACN = 2048;
  if (HAL_RCC_OscConfig(&RCC_OscInitStruct) != HAL_OK)
  {
    Error_Handler();
  }

  /** Initializes the CPU, AHB and APB buses clocks
  */
  RCC_ClkInitStruct.ClockType = RCC_CLOCKTYPE_HCLK|RCC_CLOCKTYPE_SYSCLK
                              |RCC_CLOCKTYPE_PCLK1|RCC_CLOCKTYPE_PCLK2
                              |RCC_CLOCKTYPE_PCLK3;
  RCC_ClkInitStruct.SYSCLKSource = RCC_SYSCLKSOURCE_PLLCLK;
  RCC_ClkInitStruct.AHBCLKDivider = RCC_SYSCLK_DIV1;
  RCC_ClkInitStruct.APB1CLKDivider = RCC_HCLK_DIV1;
  RCC_ClkInitStruct.APB2CLKDivider = RCC_HCLK_DIV1;
  RCC_ClkInitStruct.APB3CLKDivider = RCC_HCLK_DIV1;

  if (HAL_RCC_ClockConfig(&RCC_ClkInitStruct, FLASH_LATENCY_4) != HAL_OK)
  {
    Error_Handler();
  }

  /** Configure the programming delay
  */
  __HAL_FLASH_SET_PROGRAM_DELAY(FLASH_PROGRAMMING_DELAY_2);
}

static void MX_ADC1_Init(void)
{

  ADC_ChannelConfTypeDef sConfig = {0};

  /** Common config
  */
  hadc1.Instance = ADC1;
  hadc1.Init.ClockPrescaler = ADC_CLOCK_ASYNC_DIV4;
  hadc1.Init.Resolution = ADC_RESOLUTION_12B;
  hadc1.Init.DataAlign = ADC_DATAALIGN_RIGHT;
  hadc1.Init.ScanConvMode = ADC_SCAN_ENABLE;
  hadc1.Init.EOCSelection = ADC_EOC_SINGLE_CONV;
  hadc1.Init.LowPowerAutoWait = DISABLE;
  hadc1.Init.ContinuousConvMode = ENABLE;
  hadc1.Init.NbrOfConversion = 9;
  hadc1.Init.DiscontinuousConvMode = DISABLE;
  hadc1.Init.ExternalTrigConv = ADC_SOFTWARE_START;
  hadc1.Init.ExternalTrigConvEdge = ADC_EXTERNALTRIGCONVEDGE_NONE;
  hadc1.Init.DMAContinuousRequests = ENABLE;
  hadc1.Init.SamplingMode = ADC_SAMPLING_MODE_NORMAL;
  hadc1.Init.Overrun = ADC_OVR_DATA_OVERWRITTEN;
  hadc1.Init.OversamplingMode = DISABLE;
  if (HAL_ADC_Init(&hadc1) != HAL_OK)
  {
    Error_Handler();
  }

  /** Configure Regular Channel
  */
  sConfig.Channel = ADC_CHANNEL_3;
  sConfig.Rank = ADC_REGULAR_RANK_1;
  sConfig.SamplingTime = ADC_SAMPLETIME_6CYCLES_5;
  sConfig.SingleDiff = ADC_SINGLE_ENDED;
  sConfig.OffsetNumber = ADC_OFFSET_NONE;
  sConfig.Offset = 0;
  if (HAL_ADC_ConfigChannel(&hadc1, &sConfig) != HAL_OK)
  {
    Error_Handler();
  }

  /** Configure Regular Channel
  */
  sConfig.Channel = ADC_CHANNEL_7;
  sConfig.Rank = ADC_REGULAR_RANK_2;
  if (HAL_ADC_ConfigChannel(&hadc1, &sConfig) != HAL_OK)
  {
    Error_Handler();
  }

  /** Configure Regular Channel
  */
  sConfig.Channel = ADC_CHANNEL_8;
  sConfig.Rank = ADC_REGULAR_RANK_3;
  if (HAL_ADC_ConfigChannel(&hadc1, &sConfig) != HAL_OK)
  {
    Error_Handler();
  }

  /** Configure Regular Channel
  */
  sConfig.Channel = ADC_CHANNEL_10;
  sConfig.Rank = ADC_REGULAR_RANK_4;
  if (HAL_ADC_ConfigChannel(&hadc1, &sConfig) != HAL_OK)
  {
    Error_Handler();
  }

  /** Configure Regular Channel
  */
  sConfig.Channel = ADC_CHANNEL_11;
  sConfig.Rank = ADC_REGULAR_RANK_5;
  if (HAL_ADC_ConfigChannel(&hadc1, &sConfig) != HAL_OK)
  {
    Error_Handler();
  }

  /** Configure Regular Channel
  */
  sConfig.Channel = ADC_CHANNEL_12;
  sConfig.Rank = ADC_REGULAR_RANK_6;
  if (HAL_ADC_ConfigChannel(&hadc1, &sConfig) != HAL_OK)
  {
    Error_Handler();
  }

  /** Configure Regular Channel
  */
  sConfig.Channel = ADC_CHANNEL_13;
  sConfig.Rank = ADC_REGULAR_RANK_7;
  if (HAL_ADC_ConfigChannel(&hadc1, &sConfig) != HAL_OK)
  {
    Error_Handler();
  }

  /** Configure Regular Channel
  */
  sConfig.Channel = ADC_CHANNEL_18;
  sConfig.Rank = ADC_REGULAR_RANK_8;
  if (HAL_ADC_ConfigChannel(&hadc1, &sConfig) != HAL_OK)
  {
    Error_Handler();
  }

  /** Configure Regular Channel
  */
  sConfig.Channel = ADC_CHANNEL_19;
  sConfig.Rank = ADC_REGULAR_RANK_9;
  sConfig.SamplingTime = ADC_SAMPLETIME_24CYCLES_5;
  if (HAL_ADC_ConfigChannel(&hadc1, &sConfig) != HAL_OK)
  {
    Error_Handler();
  }

}

static void MX_FDCAN1_Init(void)
{

  hfdcan1.Instance = FDCAN1;
  hfdcan1.Init.ClockDivider = FDCAN_CLOCK_DIV1;
  hfdcan1.Init.FrameFormat = FDCAN_FRAME_CLASSIC;
  hfdcan1.Init.Mode = FDCAN_MODE_NORMAL;
  hfdcan1.Init.AutoRetransmission = ENABLE;
  hfdcan1.Init.TransmitPause = DISABLE;
  hfdcan1.Init.ProtocolException = DISABLE;
  hfdcan1.Init.NominalPrescaler = 20;
  hfdcan1.Init.NominalSyncJumpWidth = 1;
  hfdcan1.Init.NominalTimeSeg1 = 14;
  hfdcan1.Init.NominalTimeSeg2 = 2;
  hfdcan1.Init.DataPrescaler = 20;
  hfdcan1.Init.DataSyncJumpWidth = 1;
  hfdcan1.Init.DataTimeSeg1 = 14;
  hfdcan1.Init.DataTimeSeg2 = 2;
  hfdcan1.Init.StdFiltersNbr = 1;
  hfdcan1.Init.ExtFiltersNbr = 0;
  hfdcan1.Init.TxFifoQueueMode = FDCAN_TX_FIFO_OPERATION;
  if (HAL_FDCAN_Init(&hfdcan1) != HAL_OK)
  {
    Error_Handler();
  }

}

static void MX_GPDMA1_Init(void)
{

  /* Peripheral clock enable */
  __HAL_RCC_GPDMA1_CLK_ENABLE();

  /* GPDMA1 interrupt Init */
    HAL_NVIC_SetPriority(GPDMA1_Channel1_IRQn, 0, 0);
    HAL_NVIC_EnableIRQ(GPDMA1_Channel1_IRQn);
    HAL_NVIC_SetPriority(GPDMA1_Channel2_IRQn, 0, 0);
    HAL_NVIC_EnableIRQ(GPDMA1_Channel2_IRQn);
    HAL_NVIC_SetPriority(GPDMA1_Channel4_IRQn, 0, 0);
    HAL_NVIC_EnableIRQ(GPDMA1_Channel4_IRQn);
    HAL_NVIC_SetPriority(GPDMA1_Channel5_IRQn, 0, 0);
    HAL_NVIC_EnableIRQ(GPDMA1_Channel5_IRQn);

}

static void MX_GPDMA2_Init(void)
{

  /* Peripheral clock enable */
  __HAL_RCC_GPDMA2_CLK_ENABLE();

  /* GPDMA2 interrupt Init */
    HAL_NVIC_SetPriority(GPDMA2_Channel0_IRQn, 0, 0);
    HAL_NVIC_EnableIRQ(GPDMA2_Channel0_IRQn);
    HAL_NVIC_SetPriority(GPDMA2_Channel1_IRQn, 0, 0);
    HAL_NVIC_EnableIRQ(GPDMA2_Channel1_IRQn);

}

static void MX_I2C1_Init(void)
{

  hi2c1.Instance = I2C1;
  hi2c1.Init.Timing = 0x10802D9B;
  hi2c1.Init.OwnAddress1 = 0;
  hi2c1.Init.AddressingMode = I2C_ADDRESSINGMODE_7BIT;
  hi2c1.Init.DualAddressMode = I2C_DUALADDRESS_DISABLE;
  hi2c1.Init.OwnAddress2 = 0;
  hi2c1.Init.OwnAddress2Masks = I2C_OA2_NOMASK;
  hi2c1.Init.GeneralCallMode = I2C_GENERALCALL_DISABLE;
  hi2c1.Init.NoStretchMode = I2C_NOSTRETCH_DISABLE;
  if (HAL_I2C_Init(&hi2c1) != HAL_OK)
  {
    Error_Handler();
  }

  /** Configure Analogue filter
  */
  if (HAL_I2CEx_ConfigAnalogFilter(&hi2c1, I2C_ANALOGFILTER_ENABLE) != HAL_OK)
  {
    Error_Handler();
  }

  /** Configure Digital filter
  */
  if (HAL_I2CEx_ConfigDigitalFilter(&hi2c1, 0) != HAL_OK)
  {
    Error_Handler();
  }

}

static void MX_I2C3_Init(void)
{

  hi2c3.Instance = I2C3;
  hi2c3.Init.Timing = 0x00802172;
  hi2c3.Init.OwnAddress1 = 0;
  hi2c3.Init.AddressingMode = I2C_ADDRESSINGMODE_7BIT;
  hi2c3.Init.DualAddressMode = I2C_DUALADDRESS_DISABLE;
  hi2c3.Init.OwnAddress2 = 0;
  hi2c3.Init.OwnAddress2Masks = I2C_OA2_NOMASK;
  hi2c3.Init.GeneralCallMode = I2C_GENERALCALL_DISABLE;
  hi2c3.Init.NoStretchMode = I2C_NOSTRETCH_DISABLE;
  if (HAL_I2C_Init(&hi2c3) != HAL_OK)
  {
    Error_Handler();
  }

  /** Configure Analogue filter
  */
  if (HAL_I2CEx_ConfigAnalogFilter(&hi2c3, I2C_ANALOGFILTER_ENABLE) != HAL_OK)
  {
    Error_Handler();
  }

  /** Configure Digital filter
  */
  if (HAL_I2CEx_ConfigDigitalFilter(&hi2c3, 0) != HAL_OK)
  {
    Error_Handler();
  }

  /** I2C Fast mode Plus enable
  */
  if (HAL_I2CEx_ConfigFastModePlus(&hi2c3, I2C_FASTMODEPLUS_ENABLE) != HAL_OK)
  {
    Error_Handler();
  }

}

static void MX_TIM3_Init(void)
{

  TIM_MasterConfigTypeDef sMasterConfig = {0};
  TIM_OC_InitTypeDef sConfigOC = {0};

  htim3.Instance = TIM3;
  htim3.Init.Prescaler = 0;
  htim3.Init.CounterMode = TIM_COUNTERMODE_UP;
  htim3.Init.Period = 65535;
  htim3.Init.ClockDivision = TIM_CLOCKDIVISION_DIV1;
  htim3.Init.AutoReloadPreload = TIM_AUTORELOAD_PRELOAD_DISABLE;
  if (HAL_TIM_PWM_Init(&htim3) != HAL_OK)
  {
    Error_Handler();
  }
  sMasterConfig.MasterOutputTrigger = TIM_TRGO_RESET;
  sMasterConfig.MasterSlaveMode = TIM_MASTERSLAVEMODE_DISABLE;
  if (HAL_TIMEx_MasterConfigSynchronization(&htim3, &sMasterConfig) != HAL_OK)
  {
    Error_Handler();
  }
  sConfigOC.OCMode = TIM_OCMODE_PWM1;
  sConfigOC.Pulse = 0;
  sConfigOC.OCPolarity = TIM_OCPOLARITY_HIGH;
  sConfigOC.OCFastMode = TIM_OCFAST_DISABLE;
  if (HAL_TIM_PWM_ConfigChannel(&htim3, &sConfigOC, TIM_CHANNEL_1) != HAL_OK)
  {
    Error_Handler();
  }
  HAL_TIM_MspPostInit(&htim3);

}

static void MX_TIM4_Init(void)
{

  TIM_MasterConfigTypeDef sMasterConfig = {0};

  htim4.Instance = TIM4;
  htim4.Init.Prescaler = 17000-1;
  htim4.Init.CounterMode = TIM_COUNTERMODE_UP;
  htim4.Init.Period = 65535;
  htim4.Init.ClockDivision = TIM_CLOCKDIVISION_DIV1;
  htim4.Init.AutoReloadPreload = TIM_AUTORELOAD_PRELOAD_DISABLE;
  if (HAL_TIM_OnePulse_Init(&htim4, TIM_OPMODE_SINGLE) != HAL_OK)
  {
    Error_Handler();
  }
  sMasterConfig.MasterOutputTrigger = TIM_TRGO_RESET;
  sMasterConfig.MasterSlaveMode = TIM_MASTERSLAVEMODE_DISABLE;
  if (HAL_TIMEx_MasterConfigSynchronization(&htim4, &sMasterConfig) != HAL_OK)
  {
    Error_Handler();
  }

}

static void MX_TIM5_Init(void)
{

  TIM_MasterConfigTypeDef sMasterConfig = {0};

  htim5.Instance = TIM5;
  htim5.Init.Prescaler = 17000-1;
  htim5.Init.CounterMode = TIM_COUNTERMODE_UP;
  htim5.Init.Period = 65535;
  htim5.Init.ClockDivision = TIM_CLOCKDIVISION_DIV1;
  htim5.Init.AutoReloadPreload = TIM_AUTORELOAD_PRELOAD_DISABLE;
  if (HAL_TIM_OnePulse_Init(&htim5, TIM_OPMODE_SINGLE) != HAL_OK)
  {
    Error_Handler();
  }
  sMasterConfig.MasterOutputTrigger = TIM_TRGO_RESET;
  sMasterConfig.MasterSlaveMode = TIM_MASTERSLAVEMODE_DISABLE;
  if (HAL_TIMEx_MasterConfigSynchronization(&htim5, &sMasterConfig) != HAL_OK)
  {
    Error_Handler();
  }

}

static void MX_TIM6_Init(void)
{

  TIM_MasterConfigTypeDef sMasterConfig = {0};

  htim6.Instance = TIM6;
  htim6.Init.Prescaler = 17000-1;
  htim6.Init.CounterMode = TIM_COUNTERMODE_UP;
  htim6.Init.Period = 65535;
  htim6.Init.AutoReloadPreload = TIM_AUTORELOAD_PRELOAD_DISABLE;
  if (HAL_TIM_Base_Init(&htim6) != HAL_OK)
  {
    Error_Handler();
  }
  sMasterConfig.MasterOutputTrigger = TIM_TRGO_RESET;
  sMasterConfig.MasterSlaveMode = TIM_MASTERSLAVEMODE_DISABLE;
  if (HAL_TIMEx_MasterConfigSynchronization(&htim6, &sMasterConfig) != HAL_OK)
  {
    Error_Handler();
  }

}

static void MX_TIM7_Init(void)
{

  TIM_MasterConfigTypeDef sMasterConfig = {0};

  htim7.Instance = TIM7;
  htim7.Init.Prescaler = 17000-1;
  htim7.Init.CounterMode = TIM_COUNTERMODE_UP;
  htim7.Init.Period = 65535;
  htim7.Init.AutoReloadPreload = TIM_AUTORELOAD_PRELOAD_DISABLE;
  if (HAL_TIM_Base_Init(&htim7) != HAL_OK)
  {
    Error_Handler();
  }
  sMasterConfig.MasterOutputTrigger = TIM_TRGO_RESET;
  sMasterConfig.MasterSlaveMode = TIM_MASTERSLAVEMODE_DISABLE;
  if (HAL_TIMEx_MasterConfigSynchronization(&htim7, &sMasterConfig) != HAL_OK)
  {
    Error_Handler();
  }

}

static void MX_TIM12_Init(void)
{

  TIM_ClockConfigTypeDef sClockSourceConfig = {0};

  htim12.Instance = TIM12;
  htim12.Init.Prescaler = 1700-1;
  htim12.Init.CounterMode = TIM_COUNTERMODE_UP;
  htim12.Init.Period = 4999;
  htim12.Init.ClockDivision = TIM_CLOCKDIVISION_DIV1;
  htim12.Init.AutoReloadPreload = TIM_AUTORELOAD_PRELOAD_DISABLE;
  if (HAL_TIM_Base_Init(&htim12) != HAL_OK)
  {
    Error_Handler();
  }
  sClockSourceConfig.ClockSource = TIM_CLOCKSOURCE_INTERNAL;
  if (HAL_TIM_ConfigClockSource(&htim12, &sClockSourceConfig) != HAL_OK)
  {
    Error_Handler();
  }

}

static void MX_TIM13_Init(void)
{

  htim13.Instance = TIM13;
  htim13.Init.Prescaler = 170-1;
  htim13.Init.CounterMode = TIM_COUNTERMODE_UP;
  htim13.Init.Period = 999;
  htim13.Init.ClockDivision = TIM_CLOCKDIVISION_DIV1;
  htim13.Init.AutoReloadPreload = TIM_AUTORELOAD_PRELOAD_DISABLE;
  if (HAL_TIM_Base_Init(&htim13) != HAL_OK)
  {
    Error_Handler();
  }

}

static void MX_TIM14_Init(void)
{

  htim14.Instance = TIM14;
  htim14.Init.Prescaler = 6800-1;
  htim14.Init.CounterMode = TIM_COUNTERMODE_UP;
  htim14.Init.Period = 999;
  htim14.Init.ClockDivision = TIM_CLOCKDIVISION_DIV1;
  htim14.Init.AutoReloadPreload = TIM_AUTORELOAD_PRELOAD_DISABLE;
  if (HAL_TIM_Base_Init(&htim14) != HAL_OK)
  {
    Error_Handler();
  }

}

static void MX_TIM15_Init(void)
{

  TIM_ClockConfigTypeDef sClockSourceConfig = {0};
  TIM_MasterConfigTypeDef sMasterConfig = {0};

  htim15.Instance = TIM15;
  htim15.Init.Prescaler = 170-1;
  htim15.Init.CounterMode = TIM_COUNTERMODE_UP;
  htim15.Init.Period = 65535;
  htim15.Init.ClockDivision = TIM_CLOCKDIVISION_DIV1;
  htim15.Init.RepetitionCounter = 0;
  htim15.Init.AutoReloadPreload = TIM_AUTORELOAD_PRELOAD_DISABLE;
  if (HAL_TIM_Base_Init(&htim15) != HAL_OK)
  {
    Error_Handler();
  }
  sClockSourceConfig.ClockSource = TIM_CLOCKSOURCE_INTERNAL;
  if (HAL_TIM_ConfigClockSource(&htim15, &sClockSourceConfig) != HAL_OK)
  {
    Error_Handler();
  }
  sMasterConfig.MasterOutputTrigger = TIM_TRGO_RESET;
  sMasterConfig.MasterSlaveMode = TIM_MASTERSLAVEMODE_DISABLE;
  if (HAL_TIMEx_MasterConfigSynchronization(&htim15, &sMasterConfig) != HAL_OK)
  {
    Error_Handler();
  }

}

static void MX_TIM16_Init(void)
{

  htim16.Instance = TIM16;
  htim16.Init.Prescaler = 170-1;
  htim16.Init.CounterMode = TIM_COUNTERMODE_UP;
  htim16.Init.Period = 999;
  htim16.Init.ClockDivision = TIM_CLOCKDIVISION_DIV1;
  htim16.Init.RepetitionCounter = 0;
  htim16.Init.AutoReloadPreload = TIM_AUTORELOAD_PRELOAD_DISABLE;
  if (HAL_TIM_Base_Init(&htim16) != HAL_OK)
  {
    Error_Handler();
  }

}

static void MX_TIM17_Init(void)
{

  htim17.Instance = TIM17;
  htim17.Init.Prescaler = 1700-1;
  htim17.Init.CounterMode = TIM_COUNTERMODE_UP;
  htim17.Init.Period = 999;
  htim17.Init.ClockDivision = TIM_CLOCKDIVISION_DIV1;
  htim17.Init.RepetitionCounter = 0;
  htim17.Init.AutoReloadPreload = TIM_AUTORELOAD_PRELOAD_DISABLE;
  if (HAL_TIM_Base_Init(&htim17) != HAL_OK)
  {
    Error_Handler();
  }

}

static void MX_UART4_Init(void)
{

  huart4.Instance = UART4;
  huart4.Init.BaudRate = 115200;
  huart4.Init.WordLength = UART_WORDLENGTH_8B;
  huart4.Init.StopBits = UART_STOPBITS_1;
  huart4.Init.Parity = UART_PARITY_NONE;
  huart4.Init.Mode = UART_MODE_TX_RX;
  huart4.Init.HwFlowCtl = UART_HWCONTROL_NONE;
  huart4.Init.OverSampling = UART_OVERSAMPLING_16;
  huart4.Init.OneBitSampling = UART_ONE_BIT_SAMPLE_DISABLE;
  huart4.Init.ClockPrescaler = UART_PRESCALER_DIV1;
  huart4.AdvancedInit.AdvFeatureInit = UART_ADVFEATURE_NO_INIT;
  if (HAL_UART_Init(&huart4) != HAL_OK)
  {
    Error_Handler();
  }
  if (HAL_UARTEx_SetTxFifoThreshold(&huart4, UART_TXFIFO_THRESHOLD_1_8) != HAL_OK)
  {
    Error_Handler();
  }
  if (HAL_UARTEx_SetRxFifoThreshold(&huart4, UART_RXFIFO_THRESHOLD_1_8) != HAL_OK)
  {
    Error_Handler();
  }
  if (HAL_UARTEx_DisableFifoMode(&huart4) != HAL_OK)
  {
    Error_Handler();
  }

}

static void MX_UART5_Init(void)
{

  huart5.Instance = UART5;
  huart5.Init.BaudRate = 115200;
  huart5.Init.WordLength = UART_WORDLENGTH_8B;
  huart5.Init.StopBits = UART_STOPBITS_1;
  huart5.Init.Parity = UART_PARITY_NONE;
  huart5.Init.Mode = UART_MODE_TX_RX;
  huart5.Init.HwFlowCtl = UART_HWCONTROL_NONE;
  huart5.Init.OverSampling = UART_OVERSAMPLING_16;
  huart5.Init.OneBitSampling = UART_ONE_BIT_SAMPLE_DISABLE;
  huart5.Init.ClockPrescaler = UART_PRESCALER_DIV1;
  huart5.AdvancedInit.AdvFeatureInit = UART_ADVFEATURE_NO_INIT;
  if (HAL_UART_Init(&huart5) != HAL_OK)
  {
    Error_Handler();
  }
  if (HAL_UARTEx_SetTxFifoThreshold(&huart5, UART_TXFIFO_THRESHOLD_1_8) != HAL_OK)
  {
    Error_Handler();
  }
  if (HAL_UARTEx_SetRxFifoThreshold(&huart5, UART_RXFIFO_THRESHOLD_1_8) != HAL_OK)
  {
    Error_Handler();
  }
  if (HAL_UARTEx_DisableFifoMode(&huart5) != HAL_OK)
  {
    Error_Handler();
  }

}

static void MX_USART1_UART_Init(void)
{

  huart1.Instance = USART1;
  huart1.Init.BaudRate = 115200;
  huart1.Init.WordLength = UART_WORDLENGTH_8B;
  huart1.Init.StopBits = UART_STOPBITS_1;
  huart1.Init.Parity = UART_PARITY_NONE;
  huart1.Init.Mode = UART_MODE_TX_RX;
  huart1.Init.HwFlowCtl = UART_HWCONTROL_NONE;
  huart1.Init.OverSampling = UART_OVERSAMPLING_16;
  huart1.Init.OneBitSampling = UART_ONE_BIT_SAMPLE_DISABLE;
  huart1.Init.ClockPrescaler = UART_PRESCALER_DIV1;
  huart1.AdvancedInit.AdvFeatureInit = UART_ADVFEATURE_NO_INIT;
  if (HAL_UART_Init(&huart1) != HAL_OK)
  {
    Error_Handler();
  }
  if (HAL_UARTEx_SetTxFifoThreshold(&huart1, UART_TXFIFO_THRESHOLD_1_8) != HAL_OK)
  {
    Error_Handler();
  }
  if (HAL_UARTEx_SetRxFifoThreshold(&huart1, UART_RXFIFO_THRESHOLD_1_8) != HAL_OK)
  {
    Error_Handler();
  }
  if (HAL_UARTEx_DisableFifoMode(&huart1) != HAL_OK)
  {
    Error_Handler();
  }

}

static void MX_USART2_UART_Init(void)
{

  huart2.Instance = USART2;
  huart2.Init.BaudRate = 115200;
  huart2.Init.WordLength = UART_WORDLENGTH_8B;
  huart2.Init.StopBits = UART_STOPBITS_1;
  huart2.Init.Parity = UART_PARITY_NONE;
  huart2.Init.Mode = UART_MODE_TX_RX;
  huart2.Init.HwFlowCtl = UART_HWCONTROL_NONE;
  huart2.Init.OverSampling = UART_OVERSAMPLING_16;
  huart2.Init.OneBitSampling = UART_ONE_BIT_SAMPLE_DISABLE;
  huart2.Init.ClockPrescaler = UART_PRESCALER_DIV1;
  huart2.AdvancedInit.AdvFeatureInit = UART_ADVFEATURE_NO_INIT;
  if (HAL_UART_Init(&huart2) != HAL_OK)
  {
    Error_Handler();
  }
  if (HAL_UARTEx_SetTxFifoThreshold(&huart2, UART_TXFIFO_THRESHOLD_1_8) != HAL_OK)
  {
    Error_Handler();
  }
  if (HAL_UARTEx_SetRxFifoThreshold(&huart2, UART_RXFIFO_THRESHOLD_1_8) != HAL_OK)
  {
    Error_Handler();
  }
  if (HAL_UARTEx_DisableFifoMode(&huart2) != HAL_OK)
  {
    Error_Handler();
  }

}

static void MX_GPIO_Init(void)
{
  GPIO_InitTypeDef GPIO_InitStruct = {0};

  /* GPIO Ports Clock Enable */
  __HAL_RCC_GPIOC_CLK_ENABLE();
  __HAL_RCC_GPIOA_CLK_ENABLE();
  __HAL_RCC_GPIOB_CLK_ENABLE();
  __HAL_RCC_GPIOD_CLK_ENABLE();
  __HAL_RCC_GPIOE_CLK_ENABLE();

  /*Configure GPIO pin Output Level */
  HAL_GPIO_WritePin(GPIOB, LED_RED_Pin|LED_GREEN_Pin|LED_BLUE_Pin, GPIO_PIN_RESET);

  /*Configure GPIO pin Output Level */
  HAL_GPIO_WritePin(CAN_EN_GPIO_Port, CAN_EN_Pin, GPIO_PIN_RESET);

  /*Configure GPIO pin : START_MOD_IR1_Pin */
  GPIO_InitStruct.Pin = START_MOD_IR1_Pin;
  GPIO_InitStruct.Mode = GPIO_MODE_IT_RISING_FALLING;
  GPIO_InitStruct.Pull = GPIO_NOPULL;
  HAL_GPIO_Init(START_MOD_IR1_GPIO_Port, &GPIO_InitStruct);

  /*Configure GPIO pins : LED_RED_Pin LED_GREEN_Pin LED_BLUE_Pin */
  GPIO_InitStruct.Pin = LED_RED_Pin|LED_GREEN_Pin|LED_BLUE_Pin;
  GPIO_InitStruct.Mode = GPIO_MODE_OUTPUT_PP;
  GPIO_InitStruct.Pull = GPIO_NOPULL;
  GPIO_InitStruct.Speed = GPIO_SPEED_FREQ_LOW;
  HAL_GPIO_Init(GPIOB, &GPIO_InitStruct);

  /*Configure GPIO pin : START_MOD_IR3_Pin */
  GPIO_InitStruct.Pin = START_MOD_IR3_Pin;
  GPIO_InitStruct.Mode = GPIO_MODE_IT_RISING_FALLING;
  GPIO_InitStruct.Pull = GPIO_NOPULL;
  HAL_GPIO_Init(START_MOD_IR3_GPIO_Port, &GPIO_InitStruct);

  /*Configure GPIO pins : JOY5_Pin JOY4_Pin */
  GPIO_InitStruct.Pin = JOY5_Pin|JOY4_Pin;
  GPIO_InitStruct.Mode = GPIO_MODE_INPUT;
  GPIO_InitStruct.Pull = GPIO_PULLUP;
  HAL_GPIO_Init(GPIOD, &GPIO_InitStruct);

  /*Configure GPIO pins : JOY3_Pin JOY2_Pin JOY1_Pin */
  GPIO_InitStruct.Pin = JOY3_Pin|JOY2_Pin|JOY1_Pin;
  GPIO_InitStruct.Mode = GPIO_MODE_INPUT;
  GPIO_InitStruct.Pull = GPIO_PULLUP;
  HAL_GPIO_Init(GPIOC, &GPIO_InitStruct);

  /*Configure GPIO pin : CAN_EN_Pin */
  GPIO_InitStruct.Pin = CAN_EN_Pin;
  GPIO_InitStruct.Mode = GPIO_MODE_OUTPUT_PP;
  GPIO_InitStruct.Pull = GPIO_PULLUP;
  GPIO_InitStruct.Speed = GPIO_SPEED_FREQ_LOW;
  HAL_GPIO_Init(CAN_EN_GPIO_Port, &GPIO_InitStruct);

  /*Configure GPIO pin : START_MOD_IR_2_Pin */
  GPIO_InitStruct.Pin = START_MOD_IR_2_Pin;
  GPIO_InitStruct.Mode = GPIO_MODE_IT_RISING_FALLING;
  GPIO_InitStruct.Pull = GPIO_NOPULL;
  HAL_GPIO_Init(START_MOD_IR_2_GPIO_Port, &GPIO_InitStruct);

  /* EXTI interrupt init*/
  HAL_NVIC_SetPriority(EXTI0_IRQn, 0, 0);
  HAL_NVIC_EnableIRQ(EXTI0_IRQn);

  HAL_NVIC_SetPriority(EXTI11_IRQn, 0, 0);
  HAL_NVIC_EnableIRQ(EXTI11_IRQn);

  HAL_NVIC_SetPriority(EXTI14_IRQn, 0, 0);
  HAL_NVIC_EnableIRQ(EXTI14_IRQn);

}

/* USER CODE BEGIN 4 */
void HAL_TIM_PeriodElapsedCallback(TIM_HandleTypeDef *htim)
{
	//======================================== Start mod code
	if (htim->Instance == TIM12)
	{
		Interrupt10Hz();
	}
	if (htim->Instance == TIM15)
	{
		Interrupt(TIMEOUT);
	}

	if(htim->Instance == TIM16) //1000Hz battlee
	{
	  GET_LINE_SENSORS();
	  GET_LAST_SEEN_ROTATIONE();
	  GET_START_MOD();
	  if(Eva.State == IDLE)
	  {
		  Eva.StartDelayTimer=0;
	  }
	  else if(Eva.State == ATTACK)
	  {
		  if(Eva.AttackMode == STRAIGHT)
		  {
			  STRAIGHT_ATTACK();
		  }
		  else if(Eva.AttackMode == CURVE)
		  {
			  CURVE_ATTACK();
		  }
		  else if(Eva.AttackMode == FOLLOW_LINER)
		  {
			  FOLLOWLINER_ATTACK();
		  }
		  else if(Eva.AttackMode == FOLLOW_ATTACKER)
		  {
			  FOLLOW_ATTACKER_ATTACK();
		  }
		  else
		  {
			  STRAIGHT_ATTACK();
		  }
	  }
	  else
	  {
		  TASK_BEFORE_ATTACK();
	  }

	}

	if(htim->Instance == TIM17) //100hz everything else
	{
	   WATCHDOG();

	   //LOAD
		uint32_t total = DWT->CYCCNT;
		uint32_t total_diff = total - last_total;
		uint32_t idle_diff  = cpu_idle_cycles - last_idle;

		last_total = total;
		last_idle = cpu_idle_cycles;

		if (total_diff > 0)
			cpu_load_permille = (1000U * (total_diff - idle_diff)) / total_diff;
		else
			cpu_load_permille = 0;

		MCU_LOAD = cpu_load_permille / 10;

		if(MCU_LOAD > MCU_LOAD_MAX)
			MCU_LOAD_MAX = MCU_LOAD;
	}

	if(htim->Instance == TIM14)
	{
		OLED();
	}
}

void STRAIGHT_ATTACK()
{

	static uint16_t ComeBackLinerTimer=UINT16_MAX;
	static uint16_t GoForwardLineAttention=UINT16_MAX;
	static uint16_t BackLineOutGoDirection=LEFT;

	if(ComeBackLinerTimer < LINE_COMEBACK_TIME)
	{
		ComeBackLinerTimer++;
		SET_RAW_MOTORS(-LINE_COMEBACK_VELOCITY,-LINE_COMEBACK_VELOCITY);
		if(BackLeft.Line == OUT)
		{
			ComeBackLinerTimer=UINT16_MAX;
			GoForwardLineAttention = 0;
			BackLineOutGoDirection = RIGHT;
		}
		else if(BackRight.Line == OUT)
		{
			ComeBackLinerTimer=UINT16_MAX;
			GoForwardLineAttention = 0;
			BackLineOutGoDirection = LEFT;
		}
	}
	else if(GoForwardLineAttention < LINE_COMEBACK_TIME)
	{
		GoForwardLineAttention++;
		if(BackLineOutGoDirection == LEFT)
			SET_RAW_MOTORS(LINE_COMEBACK_VELOCITY*0.9, LINE_COMEBACK_VELOCITY);
		else //if(BackLineOutGoDirection == LEFT)
			SET_RAW_MOTORS(LINE_COMEBACK_VELOCITY, LINE_COMEBACK_VELOCITY*0.9);
	}
	else if(FrontLeft.Line == OUT || FrontRight.Line == OUT)
	{
		ComeBackLinerTimer = 0;
		SET_RAW_MOTORS(-LINE_COMEBACK_VELOCITY,-LINE_COMEBACK_VELOCITY);
	}
	else if(FrontLeft.Distance <= MIN_LIDAR_DISTANCE && FrontRight.Distance <= MIN_LIDAR_DISTANCE)
	{
		SET_MOTORS(100,100);
	}
	else if(FrontLeft.Distance <= MAX_LIDAR_DISTANCE && FrontRight.Distance <= MAX_LIDAR_DISTANCE)
	{
		SET_MOTORS(ATTACK_STRAIGHT_ATTACK_SPEED, ATTACK_STRAIGHT_ATTACK_SPEED);
	}
	else if(FrontLeft.Distance <= MAX_LIDAR_DISTANCE && FrontRight.Distance > MAX_LIDAR_DISTANCE)
	{
		SET_MOTORS(ATTACK_STRAIGHT_ATTACK_SPEED*0.9, ATTACK_STRAIGHT_ATTACK_SPEED);
	}
	else if(FrontLeft.Distance > MAX_LIDAR_DISTANCE && FrontRight.Distance <= MAX_LIDAR_DISTANCE)
	{
		SET_MOTORS(ATTACK_STRAIGHT_ATTACK_SPEED, ATTACK_STRAIGHT_ATTACK_SPEED*0.9);
	}
	else if(lastSeen == LEFT)
	{
		SET_MOTORS(-SEARCH_STRAIGHT_ATTACK_SPEED/3, SEARCH_STRAIGHT_ATTACK_SPEED);
	}
	else if(lastSeen == RIGHT)
	{
		SET_MOTORS(SEARCH_STRAIGHT_ATTACK_SPEED, -SEARCH_STRAIGHT_ATTACK_SPEED/3);
	}
	else
	{
		SET_MOTORS(SEARCH_STRAIGHT_ATTACK_SPEED, 0);
	}
}

void CURVE_ATTACK() //todo
{
	static uint16_t ComeBackLinerTimer=UINT16_MAX;
	static uint16_t GoForwardLineAttention=UINT16_MAX;
	static uint16_t BackLineOutGoDirection=LEFT;

	if(ComeBackLinerTimer < LINE_COMEBACK_TIME)
	{
		ComeBackLinerTimer++;
		SET_RAW_MOTORS(-SEARCH_STRAIGHT_ATTACK_SPEED,-SEARCH_STRAIGHT_ATTACK_SPEED);
		if(BackLeft.Line == OUT)
		{
			ComeBackLinerTimer=UINT16_MAX;
			GoForwardLineAttention = 0;
			BackLineOutGoDirection = RIGHT;
		}
		else if(BackRight.Line == OUT)
		{
			ComeBackLinerTimer=UINT16_MAX;
			GoForwardLineAttention = 0;
			BackLineOutGoDirection = LEFT;
		}
	}
	else if(GoForwardLineAttention < LINE_COMEBACK_TIME)
	{
		GoForwardLineAttention++;
		if(BackLineOutGoDirection == LEFT)
			SET_RAW_MOTORS(LINE_COMEBACK_VELOCITY*0.9, LINE_COMEBACK_VELOCITY);
		else //if(BackLineOutGoDirection == LEFT)
			SET_RAW_MOTORS(LINE_COMEBACK_VELOCITY, LINE_COMEBACK_VELOCITY*0.9);
	}
	else if(FrontLeft.Line == OUT || FrontRight.Line == OUT)
	{
		ComeBackLinerTimer = 0;
		SET_RAW_MOTORS(-LINE_COMEBACK_VELOCITY,-LINE_COMEBACK_VELOCITY);
	}
	else if(FrontLeft.Distance <= MIN_LIDAR_DISTANCE && FrontRight.Distance <= MIN_LIDAR_DISTANCE)
	{
		SET_MOTORS(100,100);
	}
	else if(FrontLeft.Distance <= MAX_LIDAR_DISTANCE && FrontRight.Distance <= MAX_LIDAR_DISTANCE)
	{
		SET_MOTORS(ATTACK_STRAIGHT_ATTACK_SPEED, ATTACK_STRAIGHT_ATTACK_SPEED);
	}
	else if(FrontLeft.Distance <= MAX_LIDAR_DISTANCE && FrontRight.Distance > MAX_LIDAR_DISTANCE)
	{
		SET_MOTORS(CURVE_ATTACK_ONE_SEE_ATTACK_SPEED_FASTER/2, CURVE_ATTACK_ONE_SEE_ATTACK_SPEED_FASTER);
	}
	else if(FrontLeft.Distance > MAX_LIDAR_DISTANCE && FrontRight.Distance <= MAX_LIDAR_DISTANCE)
	{
		SET_MOTORS(CURVE_ATTACK_ONE_SEE_ATTACK_SPEED_FASTER, CURVE_ATTACK_ONE_SEE_ATTACK_SPEED_FASTER/2);
	}
	else if(lastSeen == LEFT)
	{
		SET_MOTORS(CURVE_ATTACK_SEARCH_SPEED_SLOWER, CURVE_ATTACK_SEARCH_SPEED_FASTER);
	}
	else if(lastSeen == RIGHT)
	{
		SET_MOTORS(CURVE_ATTACK_SEARCH_SPEED_FASTER, CURVE_ATTACK_SEARCH_SPEED_SLOWER);
	}
	else
	{
		SET_MOTORS(CURVE_ATTACK_SEARCH_SPEED_FASTER, 0);
	}
}

void FOLLOWLINER_ATTACK(void)
{
    uint8_t Front;
    uint8_t Back;

    int16_t Inside;
    int16_t Outside;

    if(before_attack_rotation_direction == LEFT)
    {
        if(FrontLeft.Line == OUT && FrontRight.Line == OUT)
        {
        	SET_MOTORS(100, -100);
        }
        else
        {
            Front = FrontLeft.Line;
            Back  = BackLeft.Line;
        }
    }
    else //if(before_attack_rotation_direction == RIGHT)
    {
        if(FrontLeft.Line == OUT && FrontRight.Line == OUT)
        {
        	SET_MOTORS(-100, 100);
        }
        else
        {
            Front = FrontRight.Line;
            Back  = BackRight.Line;
        }
    }

    if(Front == OUT && Back == OUT)
    {
        // Cały bok jest na zewnątrz.
        Outside = FOLLOW_LINER_FASTER;
        Inside  = FOLLOW_LINER_SLOWER*0.8;
    }
    else if(Front == OUT && Back == IN)
    {
        // Przód jest bardziej na zewnątrz niż tył.
        Outside = FOLLOW_LINER_FASTER;
        Inside  = 10;
    }
    else if(Front == IN && Back == OUT)
    {
        // Tył jest bardziej na zewnątrz niż przód.
        // Korekcja musi być przeciwna.
        Outside = FOLLOW_LINER_SLOWER;
        Inside  = FOLLOW_LINER_FASTER;
    }
    else // Front == IN && Back == IN
    {
        // Cały robot uciekł do środka ringu.
        Outside = FOLLOW_LINER_SLOWER;
        Inside  = FOLLOW_LINER_FASTER;
    }

    if(before_attack_rotation_direction == LEFT)
    {
        SET_MOTORS(Outside, Inside);
    }
    else
    {
        SET_MOTORS(Inside, Outside);
    }
}

void FOLLOW_ATTACKER_ATTACK() //todo
{
	typedef enum {
		FOLLOW_LINE,
		ATTACK,
	} Attack_stage_t;
	static Attack_stage_t STAGE = FOLLOW_LINE;

	if(before_attack_rotation_direction == LEFT)
	{
		if(BackLeft.Distance <= LIDAR_DIST_FOR_LINE_FOLLOWER_ATCK_PLS_BE_BACK)
		{
			STAGE = ATTACK;
			lastSeen = LEFT;
		}
	}
	else //if(before_attack_rotation_direction == RIGHT)
	{
		if(BackRight.Distance <= LIDAR_DIST_FOR_LINE_FOLLOWER_ATCK_PLS_BE_BACK)
		{
			STAGE = ATTACK;
			lastSeen = RIGHT;
		}
	}

	if(STAGE == FOLLOW_LINE)
		FOLLOWLINER_ATTACK();
	else if(STAGE == ATTACK)
		CURVE_ATTACK();
}

void OLED()
{
	ssd1306_Clear();

	if(Eva.State == BEFORE_ATTACK_WAIT)
	{
		_ssd1306_WriteInTheMiddle("EVA++", 0, BIG);

		uint16_t TimeToShow = START_WAITING_TIME - Eva.StartDelayTimer - START_WAITING_TIME_HEADROOM;
		char buf[4];
		itoa(TimeToShow, buf, 10);
		_ssd1306_WriteInTheMiddle(buf, 20, SMALL);

	}
	else
	{
		//================================================ Line 1/4
		_ssd1306_SetCursor(0,0);
		if(Eva.inBattle == TRUE)
			_ssd1306_WriteString("ATCK>", SMALL);
		else
			_ssd1306_WriteString("IDLE>", SMALL);

		if(Eva.AttackMode == STRAIGHT)
			_ssd1306_WriteString("STRGH", SMALL);
		else if(Eva.AttackMode == CURVE)
			_ssd1306_WriteString("CURVE", SMALL);
		else if(Eva.AttackMode == FOLLOW_LINER)
			_ssd1306_WriteString("FOLIN", SMALL);
		else if(Eva.AttackMode == FOLLOW_ATTACKER)
			_ssd1306_WriteString("FLATK", SMALL);

		//================================================ Line 2/4
		_ssd1306_SetCursor(0,8);
		if(Eva.Voltage >= 100)
		{
			ssd1306_WriteChar(Eva.Voltage / 1000 + '0', Font_6x8);
			ssd1306_WriteChar((Eva.Voltage / 100) % 10 + '0', Font_6x8);
			ssd1306_WriteChar('.', Font_6x8);
			ssd1306_WriteChar((Eva.Voltage / 10) % 10 + '0', Font_6x8);
			ssd1306_WriteChar('v', Font_6x8);
		}
		else
		{
			ssd1306_WriteChar('0', Font_6x8);
			ssd1306_WriteChar((Eva.Voltage / 100) % 10 + '0', Font_6x8);
			ssd1306_WriteChar('.', Font_6x8);
			ssd1306_WriteChar((Eva.Voltage / 10) % 10 + '0', Font_6x8);
			ssd1306_WriteChar('v', Font_6x8);
		}
		ssd1306_WriteChar(' ', Font_6x8);
		if(Eva.DriverTemp >= 100)
		{
			ssd1306_WriteChar(Eva.DriverTemp / 100 + '0', Font_6x8);
			ssd1306_WriteChar((Eva.DriverTemp / 10) % 10 + '0', Font_6x8);
			ssd1306_WriteChar(Eva.DriverTemp % 10 + '0', Font_6x8);
			ssd1306_WriteChar('C', Font_6x8);
		}
		else
		{
			ssd1306_WriteChar('0', Font_6x8);
			ssd1306_WriteChar(Eva.DriverTemp / 10 + '0', Font_6x8);
			ssd1306_WriteChar(Eva.DriverTemp % 10 + '0', Font_6x8);
			ssd1306_WriteChar('C', Font_6x8);
		}

		//================================================ Line 3/4
		_ssd1306_SetCursor(0,16);
		//========================BACK RIGHT
		ssd1306_WriteChar('L', Font_6x8);
		if(BackRight.Line == IN)
			ssd1306_WriteChar(_CHECKBOX_EMPTY, Font_6x8);
		else
			ssd1306_WriteChar(_CHECKBOX_CHECKED, Font_6x8);
		ssd1306_WriteChar('D', Font_6x8);
		if(BackRight.Distance > MAX_LIDAR_DISTANCE)
			ssd1306_WriteChar(_CHECKBOX_EMPTY, Font_6x8);
		else
			ssd1306_WriteChar(_CHECKBOX_CHECKED, Font_6x8);

		ssd1306_WriteChar(' ', Font_6x8);

		//========================BACK LEFT
		ssd1306_WriteChar('L', Font_6x8);
		if(BackLeft.Line == IN)
			ssd1306_WriteChar(_CHECKBOX_EMPTY, Font_6x8);
		else
			ssd1306_WriteChar(_CHECKBOX_CHECKED, Font_6x8);
		ssd1306_WriteChar('D', Font_6x8);
		if(BackLeft.Distance > MAX_LIDAR_DISTANCE)
			ssd1306_WriteChar(_CHECKBOX_EMPTY, Font_6x8);
		else
			ssd1306_WriteChar(_CHECKBOX_CHECKED, Font_6x8);

		ssd1306_WriteChar(' ', Font_6x8);

		//================================================ Line 4/4
		_ssd1306_SetCursor(0,23);
		//========================BACK RIGHT
		ssd1306_WriteChar('L', Font_6x8);
		if(FrontRight.Line == IN)
			ssd1306_WriteChar(_CHECKBOX_EMPTY, Font_6x8);
		else
			ssd1306_WriteChar(_CHECKBOX_CHECKED, Font_6x8);
		ssd1306_WriteChar('D', Font_6x8);
		if(FrontRight.Distance > MAX_LIDAR_DISTANCE)
			ssd1306_WriteChar(_CHECKBOX_EMPTY, Font_6x8);
		else
			ssd1306_WriteChar(_CHECKBOX_CHECKED, Font_6x8);

		ssd1306_WriteChar(' ', Font_6x8);

		//========================BACK LEFT
		ssd1306_WriteChar('L', Font_6x8);
		if(FrontLeft.Line == IN)
			ssd1306_WriteChar(_CHECKBOX_EMPTY, Font_6x8);
		else
			ssd1306_WriteChar(_CHECKBOX_CHECKED, Font_6x8);
		ssd1306_WriteChar('D', Font_6x8);
		if(FrontLeft.Distance > MAX_LIDAR_DISTANCE)
			ssd1306_WriteChar(_CHECKBOX_EMPTY, Font_6x8);
		else
			ssd1306_WriteChar(_CHECKBOX_CHECKED, Font_6x8);

		ssd1306_WriteChar(' ', Font_6x8);
	}

	ssd1306_UpdateScreen();
}

void TASK_BEFORE_ATTACK()
{
	static uint16_t Counter=0;

	if(SPECIAL_STARTING_SEQUENCE == TRUE)
	{
		if(Eva.State == BEFORE_ATTACK_WAIT)
		{
			Eva.StartDelayTimer++;
			if(Eva.StartDelayTimer > START_WAITING_TIME - START_WAITING_TIME_HEADROOM)
				Eva.State = BEFORE_ATTACK_TASK;
		}
		else if(Eva.State == BEFORE_ATTACK_TASK)
		{
			SET_MOTORS(-GO_TO_LINE_TASK_SPEED, -GO_TO_LINE_TASK_SPEED);
			if(BackLeft.Line == OUT || BackRight.Line == OUT)
			{
				//SET_RAW_MOTORS(100,100);
				Eva.State = AFTER_TASK_RAM_QUCKIE;
				Counter=0;

			}
		}
		else if(Eva.State == AFTER_TASK_RAM_QUCKIE)
		{
			if(BackLeft.Line == IN && BackRight.Line == IN)
			{
				Eva.State = AFTER_TASK_RAM_CHILL ;
				Counter=0;
			}
			else if(BackLeft.Line == OUT)
			{
				SET_MOTORS(100,75);
			}
			else if(BackRight.Line == OUT)
			{
				SET_MOTORS(75,100);
			}
			else
			{
				SET_MOTORS(100,100);
			}
		}
		else if(Eva.State == AFTER_TASK_RAM_CHILL)
		{
			if(Eva.AttackMode == STRAIGHT || Eva.AttackMode == CURVE)
			{
				SET_MOTORS(100,100);
				Counter++;
				if(Counter > STARTING_ROAM_TIME_CHILL)
				{
					Eva.State = ATTACK;
					Counter=0;
				}
			}
			else if(Eva.AttackMode == FOLLOW_LINER || Eva.AttackMode == FOLLOW_ATTACKER)
			{
				if(before_attack_rotation_direction == LEFT)
				{
					if (FrontLeft.Line == OUT && BackLeft.Line == IN)
					{
						SET_RAW_MOTORS(0, 0);
						Eva.State = ATTACK;
					}
					else
					{
						SET_RAW_MOTORS(-AFTER_TASK_ALIGMENT_SPEED, -10);
					}
				}
				else if(before_attack_rotation_direction == RIGHT)
				{
					if (FrontRight.Line == OUT && BackRight.Line == IN)
					{
						SET_RAW_MOTORS(0, 0);
						Eva.State = ATTACK;
					}
					else
					{
						SET_RAW_MOTORS(-10,-AFTER_TASK_ALIGMENT_SPEED);
					}
				}
			}
			else
			{
				Eva.State = ATTACK;
			}
		}
	}
	else //IF start_sequence == false
	{
		Eva.State = ATTACK;
	}

}

void SET_MOTORS(int8_t l, int8_t r)
{
	uint8_t CAN_r, CAN_l;
	static uint8_t WhichFirst = 0;

	if (SWITCH_MOTORS)
	{
	    int8_t tmp = l;
	    l = r;
	    r = tmp;
	}
	if(REVERSE_RIGHT_MOTOR)
	{
		r = -r;
	}
	if(REVERSE_LEFT_MOTOR)
	{
		l = -l;
	}

	Motors.Requested.L = l;
	Motors.Requested.R = r;
	if(Settings.DONT_USE_MOTORS == TRUE)
		l = r = 0;

	l = l * LEFT_MOTOR_VELOCITY_MULTIPLIER;
	r = r * RIGHT_MOTOR_VELOCITY_MULTIPLIER;

	l = Acceleration_Compensation_L(l);
	r = Acceleration_Compensation_R(r);

	if(l > 99)
		l=99;
	else if(l<-99)
		l=-99;

	if(r>99)
		r=99;
	else if(r<-99)
		r=-99;

	/*
	//convert to canable characters
	 	 0=0
	 	 1-100 = forward
	 	 101-200 = backward
	*/

	Motors.Set.L = l;
	Motors.Set.R = r;

	if(l < 0)
		CAN_l = 100 - l;
	else
		CAN_l = l;

	if(r < 0)
		CAN_r= 100 - r;
	else
		CAN_r = r;

	if(WhichFirst == 1)
	{
		WhichFirst=0;
		CAN_TX_Header.DataLength = FDCAN_DLC_BYTES_4;
		CAN_TX[0]=CAN_ID_DRV0;
		CAN_TX[1]=0x50;
		CAN_TX[2]=CAN_l;
		CAN_TX[3]=0x01;
		HAL_FDCAN_AddMessageToTxFifoQ(&hfdcan1, &CAN_TX_Header, CAN_TX);

		CAN_TX_Header.DataLength = FDCAN_DLC_BYTES_4;
		CAN_TX[0]=CAN_ID_DRV1;
		CAN_TX[1]=0x50;
		CAN_TX[2]=CAN_r;
		CAN_TX[3]=0x01;
		HAL_FDCAN_AddMessageToTxFifoQ(&hfdcan1, &CAN_TX_Header, CAN_TX);
	}
	else
	{
		WhichFirst=1;
		CAN_TX_Header.DataLength = FDCAN_DLC_BYTES_4;
		CAN_TX[0]=CAN_ID_DRV1;
		CAN_TX[1]=0x50;
		CAN_TX[2]=CAN_r;
		CAN_TX[3]=0x01;
		HAL_FDCAN_AddMessageToTxFifoQ(&hfdcan1, &CAN_TX_Header, CAN_TX);

		CAN_TX_Header.DataLength = FDCAN_DLC_BYTES_4;
		CAN_TX[0]=CAN_ID_DRV0;
		CAN_TX[1]=0x50;
		CAN_TX[2]=CAN_l;
		CAN_TX[3]=0x01;
		HAL_FDCAN_AddMessageToTxFifoQ(&hfdcan1, &CAN_TX_Header, CAN_TX);
	}

	Motors.CAN.L = CAN_l;
	Motors.CAN.R = CAN_r;
}

void SET_RAW_MOTORS(int8_t l, int8_t r)
{
	uint8_t CAN_r, CAN_l;
	static uint8_t WhichFirst = 0;

	if (SWITCH_MOTORS)
	{
	    int8_t tmp = l;
	    l = r;
	    r = tmp;
	}
	if(REVERSE_RIGHT_MOTOR)
	{
		r = -r;
	}
	if(REVERSE_LEFT_MOTOR)
	{
		l = -l;
	}

	Motors.Requested.L = l;
	Motors.Requested.R = r;
	if(Settings.DONT_USE_MOTORS == TRUE)
		l = r = 0;

	l = l * LEFT_MOTOR_VELOCITY_MULTIPLIER;
	r = r * RIGHT_MOTOR_VELOCITY_MULTIPLIER;

	if(l > 99)
		l=99;
	else if(l<-99)
		l=-99;

	if(r>99)
		r=99;
	else if(r<-99)
		r=-99;

	/*
	//convert to canable characters
	 	 0=0
	 	 1-100 = forward
	 	 101-200 = backward
	*/

	Motors.Set.L = l;
	Motors.Set.R = r;

	if(l < 0)
		CAN_l = 100 - l;
	else
		CAN_l = l;

	if(r < 0)
		CAN_r= 100 - r;
	else
		CAN_r = r;

	if(WhichFirst == 1)
	{
		WhichFirst=0;
		CAN_TX_Header.DataLength = FDCAN_DLC_BYTES_4;
		CAN_TX[0]=CAN_ID_DRV0;
		CAN_TX[1]=0x50;
		CAN_TX[2]=CAN_l;
		CAN_TX[3]=0x01;
		HAL_FDCAN_AddMessageToTxFifoQ(&hfdcan1, &CAN_TX_Header, CAN_TX);

		CAN_TX_Header.DataLength = FDCAN_DLC_BYTES_4;
		CAN_TX[0]=CAN_ID_DRV1;
		CAN_TX[1]=0x50;
		CAN_TX[2]=CAN_r;
		CAN_TX[3]=0x01;
		HAL_FDCAN_AddMessageToTxFifoQ(&hfdcan1, &CAN_TX_Header, CAN_TX);
	}
	else
	{
		WhichFirst=1;
		CAN_TX_Header.DataLength = FDCAN_DLC_BYTES_4;
		CAN_TX[0]=CAN_ID_DRV1;
		CAN_TX[1]=0x50;
		CAN_TX[2]=CAN_r;
		CAN_TX[3]=0x01;
		HAL_FDCAN_AddMessageToTxFifoQ(&hfdcan1, &CAN_TX_Header, CAN_TX);

		CAN_TX_Header.DataLength = FDCAN_DLC_BYTES_4;
		CAN_TX[0]=CAN_ID_DRV0;
		CAN_TX[1]=0x50;
		CAN_TX[2]=CAN_l;
		CAN_TX[3]=0x01;
		HAL_FDCAN_AddMessageToTxFifoQ(&hfdcan1, &CAN_TX_Header, CAN_TX);
	}

	Motors.CAN.L = CAN_l;
	Motors.CAN.R = CAN_r;
}

void GET_LAST_SEEN_ROTATIONE()
{
	if(Eva.State == IDLE)
	{
		if(BackLeft.Distance < MIN_LIDAR_DISTANCE)
			before_attack_rotation_direction = lastSeen = LEFT;
		else if(BackRight.Distance < MIN_LIDAR_DISTANCE)
			before_attack_rotation_direction = lastSeen = RIGHT;

	}
	else if(Eva.State == ATTACK)
	{
		if(FrontLeft.Distance < MAX_LIDAR_DISTANCE)
			lastSeen = LEFT;
		else if(FrontRight.Distance < MAX_LIDAR_DISTANCE)
			lastSeen = RIGHT;
	}

}

void GET_START_MOD()
{
	static uint8_t switched_eva_state = FALSE;

	if(Settings.ALWAYS_IN_BATTLE)
	{
		Eva.State = ATTACK;
		Eva.inBattle = TRUE;
	}
	if(Eva.inBattle == FALSE)
	{
		switched_eva_state = FALSE;
		Eva.State = IDLE;
		Eva.StartDelayTimer = 0;
	}
	else if(Eva.inBattle && switched_eva_state == FALSE)
	{
		Eva.State = BEFORE_ATTACK_WAIT;
		switched_eva_state = TRUE;
	}
}

void COOKED(uint8_t error_code)
//error flag codes less than 200 has priority and HALT
{
	  //TODO buzzer?
	  if(error_code < 200)
	  {
		  ERROR_FLAG = error_code;
		  Error_Handler();
	  }
	  else
	  {
		  ERROR_FLAG = error_code;
	  }
}

void HAL_FDCAN_RxFifo0Callback(FDCAN_HandleTypeDef *hfdcan, uint32_t RxFifo0ITs)
{

	HAL_FDCAN_GetRxMessage(hfdcan, FDCAN_RX_FIFO0, &CAN_RX_Header, CAN_RX);
	HAL_FDCAN_ActivateNotification(hfdcan, FDCAN_IT_RX_FIFO0_NEW_MESSAGE, 0);
}

void LIDARS_INIT(UART_HandleTypeDef *huart, DMA_HandleTypeDef *dma, uint8_t *RX)
{
	uint8_t counter=0;

	//LIDARS OFF
	UART_TX[0] = 0x5A;
	UART_TX[1] = 0x05;
	UART_TX[2] = 0x07;
	UART_TX[3] = 0x00;
	UART_TX[4] = (UART_TX[0] + UART_TX[1] + UART_TX[2] + UART_TX[3]) % 0x100;
	counter=0;
	while(true)
	{
		HAL_UART_Transmit(huart, UART_TX, 5, LIDARS_INIT_UART_TIMEOUT);
		HAL_UART_Receive(huart, RX, 5, LIDARS_INIT_UART_TIMEOUT);

		if(RX[0] == UART_TX[0] && RX[1] == UART_TX[1] && RX[2] == UART_TX[2])
			break;
		if(counter >= MAX_RETRIES_LIDARS_INIT)
			COOKED(LIDARS_INIT_ERR);
		counter++;
	}
	counter=0;
	HAL_Delay(50);

	//LIDARS SET 250Hz
	UART_TX[0] = 0x5A;
	UART_TX[1] = 0x06;
	UART_TX[2] = 0x03;
	UART_TX[3] = 0xFA;
	UART_TX[4] = 0x00;
	UART_TX[5] = (UART_TX[0] + UART_TX[1] + UART_TX[2] + UART_TX[3]) % 0x100;
	counter=0;
	while(true)
	{
		HAL_UART_Transmit(huart, UART_TX, 6, LIDARS_INIT_UART_TIMEOUT);
		HAL_UART_Receive(huart, RX, 6, LIDARS_INIT_UART_TIMEOUT);

		if(RX[0] == UART_TX[0] && RX[1] == UART_TX[1] && RX[2] == UART_TX[2])
			break;
		if(counter >= MAX_RETRIES_LIDARS_INIT)
			COOKED(LIDARS_INIT_ERR);
		counter++;
	}
	counter=0;
	HAL_Delay(50);

	//LIDARS ON
	UART_TX[0] = 0x5A;
	UART_TX[1] = 0x05;
	UART_TX[2] = 0x07;
	UART_TX[3] = 0x01;
	UART_TX[4] = (UART_TX[0] + UART_TX[1] + UART_TX[2] + UART_TX[3]) % 0x100;
	counter=0;
	while(true)
	{
		HAL_UART_Transmit(huart, UART_TX, 5, LIDARS_INIT_UART_TIMEOUT);
		HAL_UART_Receive(huart, RX, 5, LIDARS_INIT_UART_TIMEOUT);

		if(RX[0] == UART_TX[0] && RX[1] == UART_TX[1] && RX[2] == UART_TX[2])
			break;
		if(counter >= MAX_RETRIES_LIDARS_INIT)
			COOKED(LIDARS_INIT_ERR);
		counter++;
	}
	HAL_Delay(50);

	counter=0;
	while(true)
	{

		if(huart->RxState == HAL_UART_STATE_READY && huart->gState == HAL_UART_STATE_READY && huart->ErrorCode == HAL_UART_ERROR_NONE)
			break;
		else if(counter >= MAX_RETRIES_LIDARS_INIT)
			COOKED(LIDARS_INIT_ERR);

		HAL_Delay(LIDARS_INIT_UART_TIMEOUT);
		counter++;
	}

	HAL_Delay(50);

	HAL_UART_AbortReceive(huart);
	__HAL_UART_CLEAR_OREFLAG(huart);
	huart->ErrorCode = HAL_UART_ERROR_NONE;
	huart->RxState   = HAL_UART_STATE_READY;
	huart->gState = HAL_UART_STATE_READY;
	if(HAL_UARTEx_ReceiveToIdle_DMA(huart, RX, 9) != HAL_OK)
		COOKED(LIDARS_INIT_ERR);
	__HAL_DMA_DISABLE_IT(dma, DMA_IT_HT);
}

void PLAY_FREQ(uint16_t f_hz)
{
	f_hz = f_hz * DEFAULT_SETTING_ENABLE_BUZZER;
    if (f_hz == 0) {
        __HAL_TIM_SET_COMPARE(&htim3, TIM_CHANNEL_1, 0);
        return;
    }

    // Stały PSC=169 -> licznik 1 MHz (TIMCLK 170 MHz / (169+1))
    __HAL_TIM_SET_PRESCALER(&htim3, 169);

    uint32_t arr = 1000000UL / f_hz;            // okres w tickach 1 MHz
    if (arr == 0) arr = 1;                      // minimalna wartość
    arr -= 1;                                   // rejestrowo

    __HAL_TIM_DISABLE(&htim3);
    __HAL_TIM_SET_AUTORELOAD(&htim3, (uint16_t)arr);
    __HAL_TIM_SET_COMPARE(&htim3, TIM_CHANNEL_1, (uint16_t)(((arr + 1U) >> 1)));
    __HAL_TIM_SET_COUNTER(&htim3, 0);
    __HAL_TIM_ENABLE(&htim3);
    HAL_TIM_PWM_Start(&htim3, TIM_CHANNEL_1);
}

void HAL_UARTEx_RxEventCallback(UART_HandleTypeDef *huart, uint16_t Size) //TODO TO MOZE NIE DZIALAC LOL
{
	uint16_t buffor_Dist[LIDARS_FILTERING_ARRAY_SIZE_BACK];
	uint16_t buffor_Amp[LIDARS_FILTERING_ARRAY_SIZE_BACK];
	uint16_t Dist, Temp, Amp;
	uint8_t j, k;

	if(huart->Instance == USART1)
	{
		for (int i = 1; i < 10; i++)
		{
			if (UART1_RX[(i-1)% 9] == 0x59 && UART1_RX[i%9] == 0x59)
			{
				//DISTANCE
				j = (i + 1) % 9;
				k = (i + 2) % 9;
				Dist = UART1_RX[j] + (UART1_RX[k] << 8);

				//AMPERAGE
				j = (i + 3) % 9;
				k = (i + 4) % 9;
				Amp = UART1_RX[j] + (UART1_RX[k] << 8);

				//TEMPERATURE
				j = (i + 5) % 9;
				k = (i + 6) % 9;
				Temp = UART1_RX[j] + (UART1_RX[k] << 8);

				if(Dist < MIN_LIDAR_AMP_DIST && Amp > MIN_LIDAR_AMP_DIST_AMP)
				{
					Dist=Dist;
				}
				else if(Amp < MIN_AMP_TRESCHOLD)
				{
					Dist = 65000;
				}
				else
				{
					Dist=Dist;
				}

				break;
			}
		}

		//=====MEDIAN FILTERING
		static uint16_t window1_Dist[LIDARS_FILTERING_ARRAY_SIZE_BACK];
		static uint16_t window1_Amp[LIDARS_FILTERING_ARRAY_SIZE_BACK];
		static uint8_t idx1_Dist = 0;
		static uint8_t idx1_Amp = 0;

		//Wstaw nowe wartosci
		window1_Dist[idx1_Dist] = Dist;
		window1_Amp[idx1_Amp] = Amp;

		//Przesun indeksy cyklicznie
		idx1_Dist = (idx1_Dist + 1) % LIDARS_FILTERING_ARRAY_SIZE_BACK;
		idx1_Amp = (idx1_Amp + 1) % LIDARS_FILTERING_ARRAY_SIZE_BACK;

		//Kopiuj i sortuj w jednej petli
		for (int i = 0; i < LIDARS_FILTERING_ARRAY_SIZE_BACK; i++) {
			buffor_Dist[i] = window1_Dist[i];
			buffor_Amp[i] = window1_Amp[i];
		}

		//Sortuj osobno
		SORT(buffor_Dist, LIDARS_FILTERING_ARRAY_SIZE_BACK);
		SORT(buffor_Amp, LIDARS_FILTERING_ARRAY_SIZE_BACK);

		//Wyciagnij mediany
		Dist = buffor_Dist[(uint8_t)((LIDARS_FILTERING_ARRAY_SIZE_BACK - 1) / 2)];
		Amp = buffor_Amp[(uint8_t)((LIDARS_FILTERING_ARRAY_SIZE_BACK - 1) / 2)];

		//Save results
		BackLeft.Distance = Dist;
		BackLeft.LidarAmp = Amp;
		BackLeft.LidarTemp = Temp;

		if(HAL_UARTEx_ReceiveToIdle_DMA(&huart1, UART1_RX, 9) != HAL_OK)
			COOKED(LIDARS_INIT_ERR);
		__HAL_DMA_DISABLE_IT(DMA_HANDLE_UART1, DMA_IT_HT);
	}

	if(huart->Instance == USART2)
		{
			for (int i = 1; i < 10; i++)
			{
				if (UART2_RX[(i-1)% 9] == 0x59 && UART2_RX[i%9] == 0x59)
				{
					//DISTANCE
					j = (i + 1) % 9;
					k = (i + 2) % 9;
					Dist = UART2_RX[j] + (UART2_RX[k] << 8);

					//AMPERAGE
					j = (i + 3) % 9;
					k = (i + 4) % 9;
					Amp = UART2_RX[j] + (UART2_RX[k] << 8);

					//TEMPERATURE
					j = (i + 5) % 9;
					k = (i + 6) % 9;
					Temp = UART2_RX[j] + (UART2_RX[k] << 8);

					if(Dist < MIN_LIDAR_AMP_DIST && Amp > MIN_LIDAR_AMP_DIST_AMP)
					{
						Dist=Dist;
					}
					else if(Amp < MIN_AMP_TRESCHOLD)
					{
						Dist = 65000;
					}
					else
					{
						Dist=Dist;
					}

					break;
				}
			}

			//=====MEDIAN FILTERING
			static uint16_t window2_Dist[LIDARS_FILTERING_ARRAY_SIZE_FRONT];
			static uint16_t window2_Amp[LIDARS_FILTERING_ARRAY_SIZE_FRONT];
			static uint8_t idx2_Dist = 0;
			static uint8_t idx2_Amp = 0;

			//Wstaw nowe wartosci
			window2_Dist[idx2_Dist] = Dist;
			window2_Amp[idx2_Amp] = Amp;

			//Przesun indeksy cyklicznie
			idx2_Dist = (idx2_Dist + 1) % LIDARS_FILTERING_ARRAY_SIZE_FRONT;
			idx2_Amp = (idx2_Amp + 1) % LIDARS_FILTERING_ARRAY_SIZE_FRONT;

			//Kopiuj i sortuj w jednej petli
			for (int i = 0; i < LIDARS_FILTERING_ARRAY_SIZE_FRONT; i++) {
				buffor_Dist[i] = window2_Dist[i];
				buffor_Amp[i] = window2_Amp[i];
			}

			//Sortuj osobno
			SORT(buffor_Dist, LIDARS_FILTERING_ARRAY_SIZE_FRONT);
			SORT(buffor_Amp, LIDARS_FILTERING_ARRAY_SIZE_FRONT);

			//Wyciagnij mediany
			Dist = buffor_Dist[(uint8_t)((LIDARS_FILTERING_ARRAY_SIZE_FRONT - 1) / 2)];
			Amp = buffor_Amp[(uint8_t)((LIDARS_FILTERING_ARRAY_SIZE_FRONT - 1) / 2)];

			//Save results
			FrontRight.Distance = Dist;
			FrontRight.LidarAmp = Amp;
			FrontRight.LidarTemp = Temp;

			if(HAL_UARTEx_ReceiveToIdle_DMA(&huart2, UART2_RX, 9) != HAL_OK)
				COOKED(LIDARS_INIT_ERR);
			__HAL_DMA_DISABLE_IT(DMA_HANDLE_UART2, DMA_IT_HT);
		}

	if(huart->Instance == UART4)
			{
				for (int i = 1; i < 10; i++)
				{
					if (UART4_RX[(i-1)% 9] == 0x59 && UART4_RX[i%9] == 0x59)
					{
						//DISTANCE
						j = (i + 1) % 9;
						k = (i + 2) % 9;
						Dist = UART4_RX[j] + (UART4_RX[k] << 8);

						//AMPERAGE
						j = (i + 3) % 9;
						k = (i + 4) % 9;
						Amp = UART4_RX[j] + (UART4_RX[k] << 8);

						//TEMPERATURE
						j = (i + 5) % 9;
						k = (i + 6) % 9;
						Temp = UART4_RX[j] + (UART4_RX[k] << 8);

						if(Dist < MIN_LIDAR_AMP_DIST && Amp > MIN_LIDAR_AMP_DIST_AMP)
						{
							Dist=Dist;
						}
						else if(Amp < MIN_AMP_TRESCHOLD)
						{
							Dist = 65000;
						}
						else
						{
							Dist=Dist;
						}

						break;
					}
				}

				//=====MEDIAN FILTERING
				static uint16_t window4_Dist[LIDARS_FILTERING_ARRAY_SIZE_BACK];
				static uint16_t window4_Amp[LIDARS_FILTERING_ARRAY_SIZE_BACK];
				static uint8_t idx4_Dist = 0;
				static uint8_t idx4_Amp = 0;

				//Wstaw nowe wartosci
				window4_Dist[idx4_Dist] = Dist;
				window4_Amp[idx4_Amp] = Amp;

				//Przesun indeksy cyklicznie
				idx4_Dist = (idx4_Dist + 1) % LIDARS_FILTERING_ARRAY_SIZE_BACK;
				idx4_Amp = (idx4_Amp + 1) % LIDARS_FILTERING_ARRAY_SIZE_BACK;

				//Kopiuj i sortuj w jednej petli
				for (int i = 0; i < LIDARS_FILTERING_ARRAY_SIZE_BACK; i++) {
					buffor_Dist[i] = window4_Dist[i];
					buffor_Amp[i] = window4_Amp[i];
				}

				//Sortuj osobno
				SORT(buffor_Dist, LIDARS_FILTERING_ARRAY_SIZE_BACK);
				SORT(buffor_Amp, LIDARS_FILTERING_ARRAY_SIZE_BACK);

				//Wyciagnij mediany
				Dist = buffor_Dist[(uint8_t)((LIDARS_FILTERING_ARRAY_SIZE_BACK - 1) / 2)];
				Amp = buffor_Amp[(uint8_t)((LIDARS_FILTERING_ARRAY_SIZE_BACK - 1) / 2)];

				//Save results
				BackRight.Distance = Dist;
				BackRight.LidarAmp = Amp;
				BackRight.LidarTemp = Temp;

				if(HAL_UARTEx_ReceiveToIdle_DMA(&huart4, UART4_RX, 9) != HAL_OK)
					COOKED(LIDARS_INIT_ERR);
				__HAL_DMA_DISABLE_IT(DMA_HANDLE_UART4, DMA_IT_HT);
			}

	if(huart->Instance == UART5)
			{
				for (int i = 1; i < 10; i++)
				{
					if (UART5_RX[(i-1)% 9] == 0x59 && UART5_RX[i%9] == 0x59)
					{
						//DISTANCE
						j = (i + 1) % 9;
						k = (i + 2) % 9;
						Dist = UART5_RX[j] + (UART5_RX[k] << 8);

						//AMPERAGE
						j = (i + 3) % 9;
						k = (i + 4) % 9;
						Amp = UART5_RX[j] + (UART5_RX[k] << 8);

						//TEMPERATURE
						j = (i + 5) % 9;
						k = (i + 6) % 9;
						Temp = UART5_RX[j] + (UART5_RX[k] << 8);

						if(Dist < MIN_LIDAR_AMP_DIST && Amp > MIN_LIDAR_AMP_DIST_AMP)
						{
							Dist=Dist;
						}
						else if(Amp < MIN_AMP_TRESCHOLD)
						{
							Dist = 65000;
						}
						else
						{
							Dist=Dist;
						}

						break;
					}
				}

				//=====MEDIAN FILTERING
				static uint16_t window5_Dist[LIDARS_FILTERING_ARRAY_SIZE_FRONT];
				static uint16_t window5_Amp[LIDARS_FILTERING_ARRAY_SIZE_FRONT];
				static uint8_t idx5_Dist = 0;
				static uint8_t idx5_Amp = 0;

				//Wstaw nowe wartosci
				window5_Dist[idx5_Dist] = Dist;
				window5_Amp[idx5_Amp] = Amp;

				//Przesun indeksy cyklicznie
				idx5_Dist = (idx5_Dist + 1) % LIDARS_FILTERING_ARRAY_SIZE_FRONT;
				idx5_Amp = (idx5_Amp + 1) % LIDARS_FILTERING_ARRAY_SIZE_FRONT;

				//Kopiuj i sortuj w jednej petli
				for (int i = 0; i < LIDARS_FILTERING_ARRAY_SIZE_FRONT; i++) {
					buffor_Dist[i] = window5_Dist[i];
					buffor_Amp[i] = window5_Amp[i];
				}

				//Sortuj osobno
				SORT(buffor_Dist, LIDARS_FILTERING_ARRAY_SIZE_FRONT);
				SORT(buffor_Amp, LIDARS_FILTERING_ARRAY_SIZE_FRONT);

				//Wyciagnij mediany
				Dist = buffor_Dist[(uint8_t)((LIDARS_FILTERING_ARRAY_SIZE_FRONT - 1) / 2)];
				Amp = buffor_Amp[(uint8_t)((LIDARS_FILTERING_ARRAY_SIZE_FRONT - 1) / 2)];

				//Save results
				FrontLeft.Distance = Dist;
				FrontLeft.LidarAmp = Amp;
				FrontLeft.LidarTemp = Temp;

				if(HAL_UARTEx_ReceiveToIdle_DMA(&huart5, UART5_RX, 9) != HAL_OK)
					COOKED(LIDARS_INIT_ERR);
				__HAL_DMA_DISABLE_IT(DMA_HANDLE_UART5, DMA_IT_HT);
			}

}

void SORT(uint16_t *array, uint8_t length) {
    for (int i = 0; i < length - 1; i++) {
        for (int j = 0; j < length - 1 - i; j++) {
            if (array[j] > array[j + 1]) {
                uint16_t temp = array[j];
                array[j] = array[j + 1];
                array[j + 1] = temp;
            }
        }
    }
}

void GET_LINE_SENSORS()
{
	FrontLeft.Line = IN;
	FrontLeft.RawLineA = ADC_BUFFER[0];
	FrontLeft.RawLineB = ADC_BUFFER[8];

	FrontRight.Line = IN;
	FrontRight.RawLineA = ADC_BUFFER[5];
	FrontRight.RawLineB = ADC_BUFFER[6];

	BackLeft.Line = IN;
	BackLeft.RawLineA = ADC_BUFFER[1];
	BackLeft.RawLineB = ADC_BUFFER[2];

	BackRight.Line = IN;
	BackRight.RawLineA = ADC_BUFFER[3];
	BackRight.RawLineB = ADC_BUFFER[4];

	if(DEFAULT_RING_COLOR_IS_WHITE == FALSE)
	{
		if(FrontLeft.RawLineA < WHITE_LINE_TRESCHOLD_FOR_BLACK_DOHYO && FrontLeft.RawLineB < WHITE_LINE_TRESCHOLD_FOR_BLACK_DOHYO)
			FrontLeft.Line = OUT;

		if(FrontRight.RawLineA < WHITE_LINE_TRESCHOLD_FOR_BLACK_DOHYO && FrontRight.RawLineB < WHITE_LINE_TRESCHOLD_FOR_BLACK_DOHYO)
			FrontRight.Line = OUT;

		if(BackLeft.RawLineA < WHITE_LINE_TRESCHOLD_FOR_BLACK_DOHYO && BackLeft.RawLineB < WHITE_LINE_TRESCHOLD_FOR_BLACK_DOHYO)
			BackLeft.Line = OUT;

		if(BackRight.RawLineA < WHITE_LINE_TRESCHOLD_FOR_BLACK_DOHYO && BackRight.RawLineB < WHITE_LINE_TRESCHOLD_FOR_BLACK_DOHYO)
			BackRight.Line = OUT;
	}
	else if(DEFAULT_RING_COLOR_IS_WHITE == TRUE)
	{
		if(FrontLeft.RawLineA > BLACK_LINE_TRESCHOLD_FOR_WHITE_DOHYO && FrontLeft.RawLineB > BLACK_LINE_TRESCHOLD_FOR_WHITE_DOHYO)
			FrontLeft.Line = OUT;

		if(FrontRight.RawLineA > BLACK_LINE_TRESCHOLD_FOR_WHITE_DOHYO && FrontRight.RawLineB > BLACK_LINE_TRESCHOLD_FOR_WHITE_DOHYO)
			FrontRight.Line = OUT;

		if(BackLeft.RawLineA > BLACK_LINE_TRESCHOLD_FOR_WHITE_DOHYO && BackLeft.RawLineB > BLACK_LINE_TRESCHOLD_FOR_WHITE_DOHYO)
			BackLeft.Line = OUT;

		if(BackRight.RawLineA > BLACK_LINE_TRESCHOLD_FOR_WHITE_DOHYO && BackRight.RawLineB > BLACK_LINE_TRESCHOLD_FOR_WHITE_DOHYO)
			BackRight.Line = OUT;
	}
}

void WATCHDOG()
{
	if(Eva.State == IDLE)
	{
		static uint8_t WHICH_DRIVER_TO_ASK = FALSE;

		if(WHICH_DRIVER_TO_ASK == TRUE)
		{
			WHICH_DRIVER_TO_ASK = !WHICH_DRIVER_TO_ASK;

			CAN_TX_Header.DataLength = FDCAN_DLC_BYTES_4;
			CAN_TX[0]=CAN_ID_DRV0;
			CAN_TX[1]=0x50;
			CAN_TX[2]=0x00;
			CAN_TX[3]=0x00;
			HAL_FDCAN_AddMessageToTxFifoQ(&hfdcan1, &CAN_TX_Header, CAN_TX);
		}
		else
		{
			WHICH_DRIVER_TO_ASK = !WHICH_DRIVER_TO_ASK;

			CAN_TX_Header.DataLength = FDCAN_DLC_BYTES_4;
			CAN_TX[0]=CAN_ID_DRV1;
			CAN_TX[1]=0x50;
			CAN_TX[2]=0x00;
			CAN_TX[3]=0x00;
			HAL_FDCAN_AddMessageToTxFifoQ(&hfdcan1, &CAN_TX_Header, CAN_TX);
		}
	}

	Eva.DriverTemp = CAN_RX[4];
	Eva.Voltage = ADC_BUFFER[7] * BATTERY_CONSTANT * BATTERY_VOLTAGE_COMPENSATION;
	Eva.CellVoltage = Eva.Voltage / 3;

	uint8_t Jcenter = !HAL_GPIO_ReadPin(JOY1_GPIO_Port, JOY1_Pin);
	uint8_t Jup = !HAL_GPIO_ReadPin(JOY2_GPIO_Port, JOY2_Pin);
	uint8_t Jdown = !HAL_GPIO_ReadPin(JOY4_GPIO_Port, JOY4_Pin);
	uint8_t Jleft = !HAL_GPIO_ReadPin(JOY3_GPIO_Port, JOY3_Pin);
	uint8_t Jright = !HAL_GPIO_ReadPin(JOY5_GPIO_Port, JOY5_Pin);

	if(!Jcenter && !Jup && !Jdown && !Jleft && !Jright)
		Eva.Interface.Joystick = _NOTHING;

	if(Eva.Interface.Joystick != _BUTTON_REBOUNCE)
	{
		if(Jcenter)
			Eva.Interface.Joystick=_CENTER;
		else if(Jup)
			Eva.Interface.Joystick=_UP;
		else if(Jleft)
			Eva.Interface.Joystick=_LEFT;
		else if(Jdown)
			Eva.Interface.Joystick=_DOWN;
		else if(Jright)
			Eva.Interface.Joystick=_RIGHT;
		else
			Eva.Interface.Joystick = _NOTHING;
	}

	if(Eva.Interface.Joystick == _CENTER)
	{
		Eva.inBattle = !Eva.inBattle;
		Eva.Interface.Joystick = _BUTTON_REBOUNCE;
	}
	else if(Eva.Interface.Joystick == _LEFT && Eva.State == IDLE)
	{
		Eva.AttackMode = (Eva.AttackMode + COUNT - 1) % COUNT;
		Eva.Interface.Joystick = _BUTTON_REBOUNCE;
	}
	else if(Eva.Interface.Joystick == _RIGHT && Eva.State == IDLE)
	{
		Eva.AttackMode = (Eva.AttackMode + 1) % COUNT;
		Eva.Interface.Joystick = _BUTTON_REBOUNCE;
	}
}

static inline void DWT_Init(void)
{
    CoreDebug->DEMCR |= CoreDebug_DEMCR_TRCENA_Msk;
    DWT->CYCCNT = 0;
    DWT->CTRL |= DWT_CTRL_CYCCNTENA_Msk;
}

void _ssd1306_WriteInTheMiddle(char *text, uint8_t y, uint8_t font)
{
	int8_t x;
	uint8_t textSize = strlen(text);

	if(font == BIG) //max = 6
	{
		x = (int)(SSD1306_WIDTH - textSize*11)/2;
		if(x < -3)
		{
			text="ERo_L";
			x = 0;
		}
		else if(x < 0)
			x = 0;
		_ssd1306_SetCursor(x, y);
		ssd1306_WriteString(text, Font_11x18);
	}
	else if(font == SMALL) //max = 11
	{
		x = (int)(SSD1306_WIDTH - textSize*6)/2;
		if(x < -2)
		{
			text="ERo_L";
			x = 0;
		}
		else if(x < 0)
			x = 0;
		_ssd1306_SetCursor(x, y);
		ssd1306_WriteString(text, Font_6x8);
	}

}

void _ssd1306_WriteString(char* str, uint8_t font)
{
	if(font == BIG)
	{
		ssd1306_WriteString(str, Font_11x18);
	}
	else if(font == SMALL)
	{
		ssd1306_WriteString(str, Font_6x8);
	}
}

void MOTOR_DRIVER_INIT(uint8_t DRV_SELF_ADDRESS)
{
	uint8_t counter;
	uint32_t req;

	//set motor temperature limits
	CAN_TX_Header.DataLength = FDCAN_DLC_BYTES_3;
	counter=0;
	CAN_TX[0] = DRV_SELF_ADDRESS;
	CAN_TX[1] = 0x12;
	CAN_TX[2] = MAX_FET_TEMP;
	while(ARE_ELEMENTS_EQUAL(CAN_TX, CAN_RX, 3) == FALSE)
	{
		req = HAL_FDCAN_GetLatestTxFifoQRequestBuffer(&hfdcan1);
		if (HAL_FDCAN_IsTxBufferMessagePending(&hfdcan1, req))
		{
			HAL_FDCAN_AbortTxRequest(&hfdcan1, req);
		}
		HAL_FDCAN_AddMessageToTxFifoQ(&hfdcan1, &CAN_TX_Header, CAN_TX);
		if (counter > MAX_RETRIES_DRIVER_INIT)
		  COOKED(DRV_INIT_ERROR);

		counter++;
		HAL_Delay(DRIVER_INIT_CAN_TIMEOUT);
	}

	// set motor Current limits
	CAN_TX_Header.DataLength = FDCAN_DLC_BYTES_3;
	counter=0;
	CAN_TX[0] = DRV_SELF_ADDRESS;
	CAN_TX[1] = 0x13;
	CAN_TX[2] = MAX_MOTOR_CURRENT_SHORT;
	while(ARE_ELEMENTS_EQUAL(CAN_TX, CAN_RX, 3) == FALSE)
	{
		req = HAL_FDCAN_GetLatestTxFifoQRequestBuffer(&hfdcan1);
		if (HAL_FDCAN_IsTxBufferMessagePending(&hfdcan1, req))
		{
			HAL_FDCAN_AbortTxRequest(&hfdcan1, req);
		}
		HAL_FDCAN_AddMessageToTxFifoQ(&hfdcan1, &CAN_TX_Header, CAN_TX);
		if (counter > MAX_RETRIES_DRIVER_INIT)
		  COOKED(DRV_INIT_ERROR);

		counter++;
		HAL_Delay(DRIVER_INIT_CAN_TIMEOUT);
	}

	// set motor constant current limits
	CAN_TX_Header.DataLength = FDCAN_DLC_BYTES_3;
	counter=0;
	CAN_TX[0] = DRV_SELF_ADDRESS;
	CAN_TX[1] = 0x14;
	CAN_TX[2] = MAX_MOTOR_CURRENT_LONG;
	while(ARE_ELEMENTS_EQUAL(CAN_TX, CAN_RX, 3) == FALSE)
	{
		req = HAL_FDCAN_GetLatestTxFifoQRequestBuffer(&hfdcan1);
		if (HAL_FDCAN_IsTxBufferMessagePending(&hfdcan1, req))
		{
			HAL_FDCAN_AbortTxRequest(&hfdcan1, req);
		}
		HAL_FDCAN_AddMessageToTxFifoQ(&hfdcan1, &CAN_TX_Header, CAN_TX);
		if (counter > MAX_RETRIES_DRIVER_INIT)
		  COOKED(DRV_INIT_ERROR);

		counter++;
		HAL_Delay(DRIVER_INIT_CAN_TIMEOUT);
	}

	// set motor max acceleration
	CAN_TX_Header.DataLength = FDCAN_DLC_BYTES_4;
	counter=0;
	CAN_TX[0] = DRV_SELF_ADDRESS;
	CAN_TX[1] = 0x15;
	CAN_TX[2] = MAX_MOTOR_ACCELERATION;
	CAN_TX[3] = MAX_MOTOR_ACCELERATION;
	while(ARE_ELEMENTS_EQUAL(CAN_TX, CAN_RX, 4) == FALSE)
	{
		req = HAL_FDCAN_GetLatestTxFifoQRequestBuffer(&hfdcan1);
		if (HAL_FDCAN_IsTxBufferMessagePending(&hfdcan1, req))
		{
			HAL_FDCAN_AbortTxRequest(&hfdcan1, req);
		}
		HAL_FDCAN_AddMessageToTxFifoQ(&hfdcan1, &CAN_TX_Header, CAN_TX);
		if (counter > MAX_RETRIES_DRIVER_INIT)
		  COOKED(DRV_INIT_ERROR);

		counter++;
		HAL_Delay(DRIVER_INIT_CAN_TIMEOUT);
	}
}

uint8_t ARE_ELEMENTS_EQUAL(const uint8_t *a, const uint8_t *b, uint8_t n)
{
    for (uint8_t i = 0; i < n; i++) {
        if (*(a + i) != *(b + i)) {
            return false;
        }
    }
    return true;
}

int8_t Acceleration_Compensation_L(int8_t Duty)
{
    static int16_t current_duty = 0;
    static int16_t start_duty = 0;
    static int16_t target_duty = 0;
    static int16_t ramp_delta = 0;
    uint16_t t_ms;
    t_ms = __HAL_TIM_GET_COUNTER(&htim6) / 10;

    if(MAX_MOTOR_ACCELERATION_NOT_DECELERATION_BY_CONTROLLER == 0)
    {
        return Duty;
    }
    else if (Duty <= current_duty)
    {
    	HAL_TIM_Base_Stop(&htim6);
    	return current_duty = start_duty = target_duty = Duty;
    }
    else if(target_duty != Duty)
    {
        current_duty = start_duty + (int32_t)ramp_delta * t_ms / MAX_MOTOR_ACCELERATION_NOT_DECELERATION_BY_CONTROLLER;

        start_duty = current_duty;
        target_duty = Duty;
        ramp_delta = target_duty - start_duty;

        __HAL_TIM_SET_COUNTER(&htim6, 0);
        HAL_TIM_Base_Start(&htim6);

        return current_duty;
    }

    if(t_ms >= MAX_MOTOR_ACCELERATION_NOT_DECELERATION_BY_CONTROLLER)
    {
        HAL_TIM_Base_Stop(&htim6);
        current_duty = target_duty;
        return current_duty;
    }

    current_duty = start_duty + (int32_t)ramp_delta * t_ms / MAX_MOTOR_ACCELERATION_NOT_DECELERATION_BY_CONTROLLER;

    return current_duty;
}

int8_t Acceleration_Compensation_R(int8_t Duty)
{
    static int16_t current_duty = 0;
    static int16_t start_duty = 0;
    static int16_t target_duty = 0;
    static int16_t ramp_delta = 0;
    uint16_t t_ms;
    t_ms = __HAL_TIM_GET_COUNTER(&htim7) / 10;

    if(MAX_MOTOR_ACCELERATION_NOT_DECELERATION_BY_CONTROLLER == 0)
    {
        return Duty;
    }
    else if (Duty <= current_duty)
    {
    	HAL_TIM_Base_Stop(&htim7);
    	return current_duty = start_duty = target_duty = Duty;
    }
    else if(target_duty != Duty)
    {
        current_duty = start_duty + (int32_t)ramp_delta * t_ms / MAX_MOTOR_ACCELERATION_NOT_DECELERATION_BY_CONTROLLER;

        start_duty = current_duty;
        target_duty = Duty;
        ramp_delta = target_duty - start_duty;

        __HAL_TIM_SET_COUNTER(&htim7, 0);
        HAL_TIM_Base_Start(&htim7);

        return current_duty;
    }

    if(t_ms >= MAX_MOTOR_ACCELERATION_NOT_DECELERATION_BY_CONTROLLER)
    {
        HAL_TIM_Base_Stop(&htim7);
        current_duty = target_duty;
        return current_duty;
    }

    current_duty = start_duty + (int32_t)ramp_delta * t_ms / MAX_MOTOR_ACCELERATION_NOT_DECELERATION_BY_CONTROLLER;

    return current_duty;
}

//=============================================================================================================
//=============================================================================================================
//=============================================================================================================			START MOD CODE
//=============================================================================================================
//=============================================================================================================

void HAL_GPIO_EXTI_Rising_Callback(uint16_t GPIO_Pin)
{
	if (GPIO_Pin == START_MOD_IR3_Pin)
	{
		dupa++;
		Interrupt(RISING);
	}
}
void HAL_GPIO_EXTI_Falling_Callback(uint16_t GPIO_Pin)
{
	if (GPIO_Pin == START_MOD_IR3_Pin)
	{
		dupa++;
		Interrupt(FALLING);
	}
}

void Interrupt10Hz(void)
{
	LED_BLUE_Control(TICK, 0);
	LED_RED_Control(TICK, 0);
	LED_GREEN_Control(TICK, 0);
}

void Interrupt(uint8_t Edge)
{
	static uint8_t 		Last_Edge;
	static uint8_t 		Bit_Nbr;
	static uint16_t 	IR_Buffer;
	static uint8_t		Line_Iddle;
	static uint8_t		IR_Protocol;

	uint32_t 	Timer; // 10ticks = 1uS
	uint16_t 	shift;
	uint8_t		Address;
	uint8_t		Command;

	Timer = TIM15->CNT;

	if (Module_State == RC5_START)
		IR_Protocol = RC5;
	else if (Module_State == SIRC_START)
		IR_Protocol = SIRC;

	if (Edge == TIMEOUT)
	{
	    Line_Iddle = 0;
	    Bit_Nbr = 0;
	    IR_Buffer = 0;
	    IR_Protocol = UNKNOWN;
	}

	else if (Line_Iddle == 0 && Edge == FALLING)
	{
		TIM15->CNT = 0;
		Line_Iddle = 1;
		Bit_Nbr = 0;
		IR_Buffer = 0;
	}
	else if (Line_Iddle == 0 && Edge == RISING)
		TIM15->CNT = 0;

// Check if selected protocol
	else if (IR_Protocol == UNKNOWN)	// Second Interrupt. Protocol yet unknown
	{
		if (Last_Edge == FALLING && Edge == RISING && (Timer >= RC5_Short-Margin && Timer <= RC5_Short + Margin))
			IR_Protocol = RC5;

		else if (Last_Edge == FALLING && Edge == RISING && (Timer >= 2*SIRC_Long - 2*Margin && Timer <= 2*SIRC_Long + 2*Margin))
		{
			IR_Protocol = SIRC;
			TIM15->CNT = 0;
		}
		else
			Line_Iddle = 0; 	// Error - Restart communication
	}

	else if (IR_Protocol == RC5)
	{
		if (Timer >= RC5_Long - Margin && Timer <= RC5_Long + Margin) // Received Bit
		{
			TIM15->CNT = 0;
			// Received 0
			if (Edge == RISING)
				Bit_Nbr ++;

			// Received 1
			else if (Edge == FALLING)
			{
				Bit_Nbr ++;
				shift = 15 - Bit_Nbr;
				IR_Buffer = IR_Buffer | 0b1 << shift;
			}
		}

		else if (Timer >= RC5_Long + Margin)
			Line_Iddle = 0;

		if (Bit_Nbr == 13)
		{
			Line_Iddle = 0;
			Address = (IR_Buffer >> 8) & 0b00011111;
			Command = (IR_Buffer >> 2) & 0b00111111;
			Received_RC5_Frame(Address, Command);
		}
	}
	else if (IR_Protocol == SIRC)
	{
		TIM15->CNT = 0;
		// Begin of Frame
		if (Edge == RISING && (Timer >= 2*SIRC_Long - 2*Margin && Timer <= 2*SIRC_Long + 2*Margin))
			Bit_Nbr = 0;

		// Received 1
		else if (Edge == RISING && (Timer >= SIRC_Long - Margin && Timer <= SIRC_Long + Margin))
		{
			Bit_Nbr ++;
			shift = Bit_Nbr - 1;
			IR_Buffer = IR_Buffer | 0b1 << shift;
		}

		// Received 0
		else if (Edge == RISING && (Timer >= SIRC_Short - Margin && Timer <= SIRC_Short + Margin))
			Bit_Nbr ++;

		if (Bit_Nbr == 12)
		{
			Line_Iddle = 0;
			Command = IR_Buffer & 0b01111111;
			Address = (IR_Buffer >> 7)  & 0b00011111;
			Received_SIRC_Frame(Address, Command);
		}

	}

	if (Edge != TIMEOUT)
		Last_Edge = Edge;

}

void Received_RC5_Frame(uint8_t Addres, uint8_t Command)
{
	uint8_t StartCommand;
	StartCommand = Command & 0x01;

	if (Addres == 0x0B) // Programming Frame
	{
		if (Module_State == STARTUP)
		{
			LED_GREEN_Control(BLINK_SLOW, 2);
			if ((Command >> 1) != Dohyo_ID)
			{
				Dohyo_ID = Command >> 1;
			}
			Module_State = PPROGRAMMED;
		}
		else if (Module_State == PPROGRAMMED)
		{
			LED_GREEN_Control(BLINK_FAST, 2);
			if ((Command >> 1) != Dohyo_ID)
			{
				Dohyo_ID = Command >> 1;
			}
		}
	}
	else if (Addres == 0x07) // Command Frame
	{
		if ((Command >> 1) == Dohyo_ID)
		{
			if (StartCommand == 1 && Module_State != STOP && Module_State != RC5_START)
			{
				Module_State = RC5_START;
				Eva.inBattle = TRUE;
				LED_GREEN_Control(ON, 0);
			}
			else if (StartCommand == 0 && Module_State != STOP)
			{
				//Module_State = STOP;
				Module_State = STARTUP;
				Eva.inBattle = FALSE;
				LED_GREEN_Control(BLINK_SLOW, 3);
			}
		}
	}
}
void Received_SIRC_Frame(uint8_t Addres, uint8_t Command)
{
	// Programming Frame
	if (Command == 0x7F)
	{
		if (Module_State == STARTUP || Module_State == PPROGRAMMED)
		{
			Module_State = PPROGRAMMED;
			Dohyo_ID = Addres;
			LED_BLUE_Control(BLINK_FAST, 3);
			LED_RED_Control(BLINK_FAST, 3);
		}

	}
	else if(Addres == Dohyo_ID)
	{
		if (Command == 0x06 && (Module_State == STARTUP || Module_State == PPROGRAMMED)) // Ready
		{
			Module_State = READY;
			LED_BLUE_Control(BLINK_FAST, 3);
			LED_RED_Control(ON, 0);
		}
		else if (Command == 0x07 && Module_State == READY && Module_State != SIRC_START) // Start
		{
			Module_State = SIRC_START;
			Eva.inBattle = TRUE;
			LED_BLUE_Control(ON, 0);
			LED_RED_Control(OFF, 0);
		}
		else if (Command == 0x08 && Module_State != STOP) // Stop
		{
			//Module_State = STOP;
			Module_State = STARTUP;
			Eva.inBattle = FALSE;
			LED_BLUE_Control(BLINK_SLOW, 3);
			LED_RED_Control(BLINK_SLOW,	3);
		}
	}
}
uint8_t LED_GREEN_Control(uint8_t Command, uint8_t Data)
{
	static uint8_t LED_Status = OFF;
	static uint8_t LED_Data;
	static uint8_t Counter;

	if (LED_Status == ON || LED_Status == OFF || ((LED_Status == BLINK_FAST || LED_Status == BLINK_SLOW) && LED_Data == 255))
	{
		if (Command == ON)
		{
			HAL_GPIO_WritePin(LED_GREEN_GPIO_Port, LED_GREEN_Pin, GPIO_PIN_SET);
			LED_Status = Command;
		}
		else if (Command == OFF)
		{
			HAL_GPIO_WritePin(LED_GREEN_GPIO_Port, LED_GREEN_Pin, GPIO_PIN_RESET);
			LED_Status = Command;
		}
		else if (Command == BLINK_SLOW)
		{
			HAL_GPIO_WritePin(LED_GREEN_GPIO_Port, LED_GREEN_Pin, GPIO_PIN_RESET);
			LED_Status = Command;
			LED_Data = 6*Data;
		}
		else if (Command == BLINK_FAST)
		{
			HAL_GPIO_WritePin(LED_GREEN_GPIO_Port, LED_GREEN_Pin, GPIO_PIN_RESET);
			LED_Status = Command;
			LED_Data = 2*Data;
		}
		Counter = 0;
	}
	else if (Command == TICK)
	{
		Counter++;

		if (LED_Status == BLINK_FAST)
			HAL_GPIO_TogglePin(LED_GREEN_GPIO_Port, LED_GREEN_Pin);

		else if (LED_Status == BLINK_SLOW && (Counter % 3 == 0) )
			HAL_GPIO_TogglePin(LED_GREEN_GPIO_Port, LED_GREEN_Pin);

		if (Counter >= LED_Data && LED_Data < 100)
		{
			HAL_GPIO_WritePin(LED_GREEN_GPIO_Port, LED_GREEN_Pin, GPIO_PIN_RESET);
			LED_Status = OFF;
		}
	}
	return LED_Status;
}
uint8_t LED_RED_Control(uint8_t Command, uint8_t Data)
{
	static uint8_t LED_Status = OFF;
	static uint8_t LED_Data;
	static uint8_t Counter;

	if (LED_Status == ON || LED_Status == OFF || ((LED_Status == BLINK_FAST || LED_Status == BLINK_SLOW) && LED_Data == 255))
	{
		if (Command == ON)
		{
			HAL_GPIO_WritePin(LED_RED_GPIO_Port, LED_RED_Pin, GPIO_PIN_SET);
			LED_Status = Command;
		}
		else if (Command == OFF)
		{
			HAL_GPIO_WritePin(LED_RED_GPIO_Port, LED_RED_Pin, GPIO_PIN_RESET);
			LED_Status = Command;
		}
		else if (Command == BLINK_SLOW)
		{
			HAL_GPIO_WritePin(LED_RED_GPIO_Port, LED_RED_Pin, GPIO_PIN_RESET);
			LED_Status = Command;
			LED_Data = 6*Data;
		}
		else if (Command == BLINK_FAST)
		{
			HAL_GPIO_WritePin(LED_RED_GPIO_Port, LED_RED_Pin, GPIO_PIN_RESET);
			LED_Status = Command;
			LED_Data = 2*Data;
		}
		Counter = 0;
	}
	else if (Command == TICK)
	{
		Counter++;

		if (LED_Status == BLINK_FAST)
			HAL_GPIO_TogglePin(LED_RED_GPIO_Port, LED_RED_Pin);

		else if (LED_Status == BLINK_SLOW && (Counter % 3 == 0) )
			HAL_GPIO_TogglePin(LED_RED_GPIO_Port, LED_RED_Pin);

		if (Counter >= LED_Data && LED_Data < 100)
		{
			HAL_GPIO_WritePin(LED_RED_GPIO_Port, LED_RED_Pin, GPIO_PIN_RESET);
			LED_Status = OFF;
		}
	}
	return LED_Status;
}
uint8_t LED_BLUE_Control(uint8_t Command, uint8_t Data)
{
	static uint8_t LED_Status = OFF;
	static uint8_t LED_Data;
	static uint8_t Counter;

	if (LED_Status == ON || LED_Status == OFF || ((LED_Status == BLINK_FAST || LED_Status == BLINK_SLOW) && LED_Data == 255))
	{
		if (Command == ON)
		{
			HAL_GPIO_WritePin(LED_BLUE_GPIO_Port, LED_BLUE_Pin, GPIO_PIN_SET);
			LED_Status = Command;
		}
		else if (Command == OFF)
		{
			HAL_GPIO_WritePin(LED_BLUE_GPIO_Port, LED_BLUE_Pin, GPIO_PIN_RESET);
			LED_Status = Command;
		}
		else if (Command == BLINK_SLOW)
		{
			HAL_GPIO_WritePin(LED_BLUE_GPIO_Port, LED_BLUE_Pin, GPIO_PIN_RESET);
			LED_Status = Command;
			LED_Data = 6*Data;
		}
		else if (Command == BLINK_FAST)
		{
			HAL_GPIO_WritePin(LED_BLUE_GPIO_Port, LED_BLUE_Pin, GPIO_PIN_RESET);
			LED_Status = Command;
			LED_Data = 2*Data;
		}
		Counter = 0;
	}
	else if (Command == TICK)
	{
		Counter++;

		if (LED_Status == BLINK_FAST)
			HAL_GPIO_TogglePin(LED_BLUE_GPIO_Port, LED_BLUE_Pin);

		else if (LED_Status == BLINK_SLOW && (Counter % 3 == 0) )
			HAL_GPIO_TogglePin(LED_BLUE_GPIO_Port, LED_BLUE_Pin);

		if (Counter >= LED_Data && LED_Data < 100)
		{
			HAL_GPIO_WritePin(LED_BLUE_GPIO_Port, LED_BLUE_Pin, GPIO_PIN_RESET);
			LED_Status = OFF;
		}
	}
	return LED_Status;
}

/* USER CODE END 4 */

void Error_Handler(void)
{
  /* USER CODE BEGIN Error_Handler_Debug */
	HAL_GPIO_WritePin(LED_RED_GPIO_Port, LED_RED_Pin, 1);
	//ssd1306_Clear();
	//_ssd1306_WriteInTheMiddle("error:", 0, SMALL);
	//_ssd1306_WriteInTheMiddle(ERROR_FLAG, 10, SMALL);
	//ssd1306_UpdateScreen();
	HAL_Delay(10);
  /* User can add his own implementation to report the HAL error return state */
  __disable_irq();
  while (1)
  {
  }
  /* USER CODE END Error_Handler_Debug */
}
